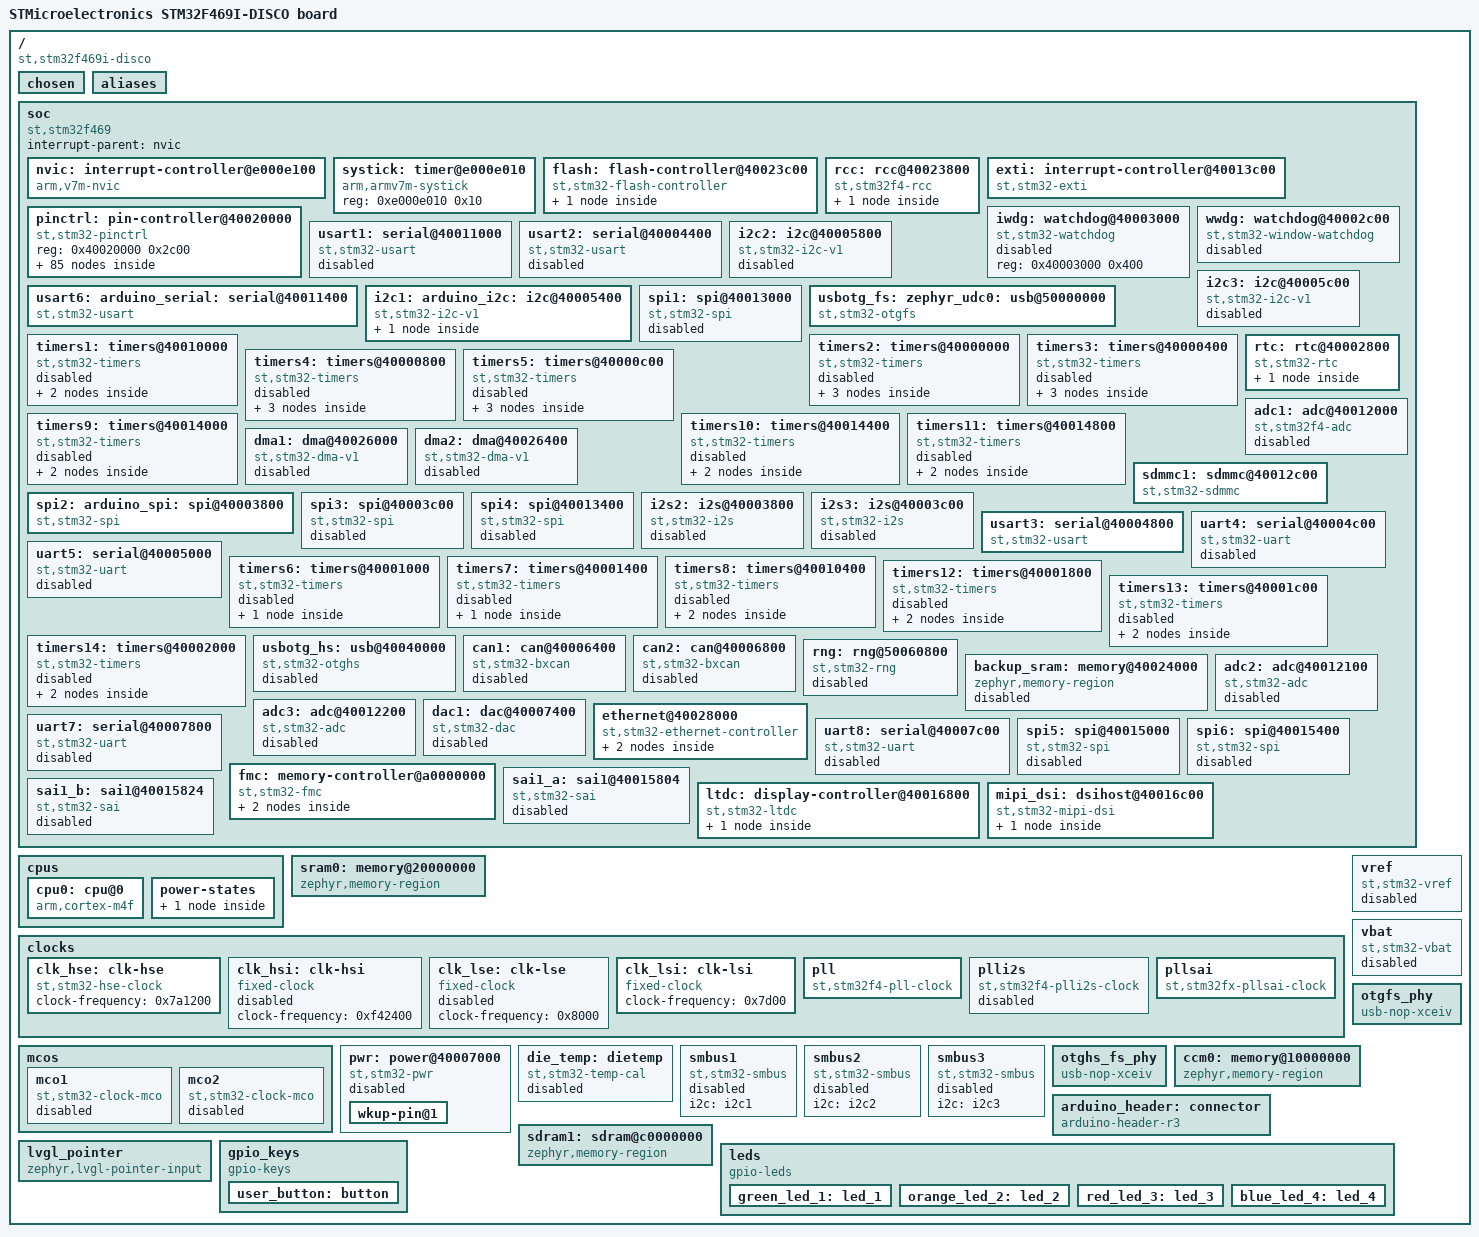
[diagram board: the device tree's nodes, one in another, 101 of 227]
/dts-v1/;

/* node '/' defined in zephyr/dts/common/skeleton.dtsi:9 */
/ {
	#address-cells = < 0x1 >;                            /* in zephyr/dts/common/skeleton.dtsi:10 */
	#size-cells = < 0x1 >;                               /* in zephyr/dts/common/skeleton.dtsi:11 */
	model = "STMicroelectronics STM32F469I-DISCO board"; /* in zephyr/boards/st/stm32f469i_disco/stm32f469i_disco.dts:14 */
	compatible = "st,stm32f469i-disco";                  /* in zephyr/boards/st/stm32f469i_disco/stm32f469i_disco.dts:15 */

	/* node '/chosen' defined in zephyr/dts/common/skeleton.dtsi:13 */
	chosen {
		zephyr,flash-controller = &flash;  /* in zephyr/dts/arm/st/f4/stm32f4.dtsi:27 */
		zephyr,cortex-m-idle-timer = &rtc; /* in zephyr/dts/arm/st/f4/stm32f4.dtsi:28 */
		zephyr,entropy = &rng;             /* in zephyr/dts/arm/st/f4/stm32f405.dtsi:13 */
		zephyr,console = &usart3;          /* in zephyr/boards/st/stm32f469i_disco/stm32f469i_disco.dts:18 */
		zephyr,shell-uart = &usart3;       /* in zephyr/boards/st/stm32f469i_disco/stm32f469i_disco.dts:19 */
		zephyr,sram = &sram0;              /* in zephyr/boards/st/stm32f469i_disco/stm32f469i_disco.dts:20 */
		zephyr,flash = &flash0;            /* in zephyr/boards/st/stm32f469i_disco/stm32f469i_disco.dts:21 */
		zephyr,ccm = &ccm0;                /* in zephyr/boards/st/stm32f469i_disco/stm32f469i_disco.dts:22 */
		zephyr,display = &ltdc;            /* in zephyr/boards/st/stm32f469i_disco/stm32f469i_disco.dts:23 */
		zephyr,touch = &ft5336;            /* in zephyr/boards/st/stm32f469i_disco/stm32f469i_disco.dts:24 */
	};

	/* node '/aliases' defined in zephyr/dts/common/skeleton.dtsi:15 */
	aliases {
		led0 = &green_led_1;  /* in zephyr/boards/st/stm32f469i_disco/stm32f469i_disco.dts:75 */
		led1 = &orange_led_2; /* in zephyr/boards/st/stm32f469i_disco/stm32f469i_disco.dts:76 */
		led2 = &red_led_3;    /* in zephyr/boards/st/stm32f469i_disco/stm32f469i_disco.dts:77 */
		led3 = &blue_led_4;   /* in zephyr/boards/st/stm32f469i_disco/stm32f469i_disco.dts:78 */
		sw0 = &user_button;   /* in zephyr/boards/st/stm32f469i_disco/stm32f469i_disco.dts:79 */
	};

	/* node '/soc' defined in zephyr/dts/arm/armv7-m.dtsi:6 */
	soc {
		#address-cells = < 0x1 >;     /* in zephyr/dts/arm/armv7-m.dtsi:7 */
		#size-cells = < 0x1 >;        /* in zephyr/dts/arm/armv7-m.dtsi:8 */
		interrupt-parent = < &nvic >; /* in zephyr/dts/arm/armv7-m.dtsi:10 */
		ranges;                       /* in zephyr/dts/arm/armv7-m.dtsi:11 */
		compatible = "st,stm32f469",
		             "st,stm32f4",
		             "simple-bus";    /* in zephyr/dts/arm/st/f4/stm32f469.dtsi:12 */

		/* node '/soc/interrupt-controller@e000e100' defined in zephyr/dts/arm/armv7-m.dtsi:13 */
		nvic: interrupt-controller@e000e100 {
			#address-cells = < 0x1 >;            /* in zephyr/dts/arm/armv7-m.dtsi:14 */
			compatible = "arm,v7m-nvic";         /* in zephyr/dts/arm/armv7-m.dtsi:15 */
			reg = < 0xe000e100 0xc00 >;          /* in zephyr/dts/arm/armv7-m.dtsi:16 */
			interrupt-controller;                /* in zephyr/dts/arm/armv7-m.dtsi:17 */
			#interrupt-cells = < 0x2 >;          /* in zephyr/dts/arm/armv7-m.dtsi:18 */
			arm,num-irq-priority-bits = < 0x4 >; /* in zephyr/dts/arm/st/f4/stm32f4.dtsi:676 */
			phandle = < 0x1 >;                   /* in zephyr/dts/arm/armv7-m.dtsi:10 */
		};

		/* node '/soc/timer@e000e010' defined in zephyr/dts/arm/armv7-m.dtsi:21 */
		systick: timer@e000e010 {
			compatible = "arm,armv7m-systick"; /* in zephyr/dts/arm/armv7-m.dtsi:22 */
			reg = < 0xe000e010 0x10 >;         /* in zephyr/dts/arm/armv7-m.dtsi:23 */
		};

		/* node '/soc/flash-controller@40023c00' defined in zephyr/dts/arm/st/f4/stm32f4.dtsi:111 */
		flash: flash-controller@40023c00 {
			compatible = "st,stm32-flash-controller",
			             "st,stm32f4-flash-controller"; /* in zephyr/dts/arm/st/f4/stm32f4.dtsi:112 */
			reg = < 0x40023c00 0x400 >;                 /* in zephyr/dts/arm/st/f4/stm32f4.dtsi:113 */
			interrupts = < 0x4 0x0 >;                   /* in zephyr/dts/arm/st/f4/stm32f4.dtsi:114 */
			#address-cells = < 0x1 >;                   /* in zephyr/dts/arm/st/f4/stm32f4.dtsi:116 */
			#size-cells = < 0x1 >;                      /* in zephyr/dts/arm/st/f4/stm32f4.dtsi:117 */

			/* node '/soc/flash-controller@40023c00/flash@8000000' defined in zephyr/dts/arm/st/f4/stm32f4.dtsi:119 */
			flash0: flash@8000000 {
				compatible = "st,stm32f4-nv-flash",
				             "st,stm32-nv-flash",
				             "soc-nv-flash";        /* in zephyr/dts/arm/st/f4/stm32f4.dtsi:120 */
				write-block-size = < 0x1 >;         /* in zephyr/dts/arm/st/f4/stm32f4.dtsi:123 */
				max-erase-time = < 0xfa0 >;         /* in zephyr/dts/arm/st/f4/stm32f4.dtsi:125 */
				reg = < 0x8000000 0x200000 >;       /* in zephyr/dts/arm/st/f4/stm32f469Xi.dtsi:23 */
			};
		};

		/* node '/soc/rcc@40023800' defined in zephyr/dts/arm/st/f4/stm32f4.dtsi:129 */
		rcc: rcc@40023800 {
			#clock-cells = < 0x2 >;          /* in zephyr/dts/arm/st/f4/stm32f4.dtsi:131 */
			reg = < 0x40023800 0x400 >;      /* in zephyr/dts/arm/st/f4/stm32f4.dtsi:132 */
			compatible = "st,stm32f4-rcc";   /* in zephyr/dts/arm/st/f4/stm32f427.dtsi:25 */
			clocks = < &pll >;               /* in zephyr/boards/st/stm32f469i_disco/stm32f469i_disco.dts:113 */
			clock-frequency = < 0xa037a00 >; /* in zephyr/boards/st/stm32f469i_disco/stm32f469i_disco.dts:114 */
			ahb-prescaler = < 0x1 >;         /* in zephyr/boards/st/stm32f469i_disco/stm32f469i_disco.dts:115 */
			apb1-prescaler = < 0x4 >;        /* in zephyr/boards/st/stm32f469i_disco/stm32f469i_disco.dts:116 */
			apb2-prescaler = < 0x2 >;        /* in zephyr/boards/st/stm32f469i_disco/stm32f469i_disco.dts:117 */
			phandle = < 0x3 >;               /* in zephyr/dts/arm/st/f4/stm32f4.dtsi:146 */

			/* node '/soc/rcc@40023800/reset-controller' defined in zephyr/dts/arm/st/f4/stm32f4.dtsi:134 */
			rctl: reset-controller {
				compatible = "st,stm32-rcc-rctl"; /* in zephyr/dts/arm/st/f4/stm32f4.dtsi:135 */
				#reset-cells = < 0x1 >;           /* in zephyr/dts/arm/st/f4/stm32f4.dtsi:136 */
				phandle = < 0x4 >;                /* in zephyr/dts/arm/st/f4/stm32f4.dtsi:245 */
			};
		};

		/* node '/soc/interrupt-controller@40013c00' defined in zephyr/dts/arm/st/f4/stm32f4.dtsi:140 */
		exti: interrupt-controller@40013c00 {
			compatible = "st,stm32-exti";  /* in zephyr/dts/arm/st/f4/stm32f4.dtsi:141 */
			interrupt-controller;          /* in zephyr/dts/arm/st/f4/stm32f4.dtsi:142 */
			#interrupt-cells = < 0x1 >;    /* in zephyr/dts/arm/st/f4/stm32f4.dtsi:143 */
			#address-cells = < 0x0 >;      /* in zephyr/dts/arm/st/f4/stm32f4.dtsi:144 */
			reg = < 0x40013c00 0x400 >;    /* in zephyr/dts/arm/st/f4/stm32f4.dtsi:145 */
			clocks = < &rcc 0x44 0x4000 >; /* in zephyr/dts/arm/st/f4/stm32f4.dtsi:146 */
			num-lines = < 0x20 >;          /* in zephyr/dts/arm/st/f4/stm32f4.dtsi:147 */
			interrupts = < 0x6 0x0 >,
			             < 0x7 0x0 >,
			             < 0x8 0x0 >,
			             < 0x9 0x0 >,
			             < 0xa 0x0 >,
			             < 0x17 0x0 >,
			             < 0x28 0x0 >;     /* in zephyr/dts/arm/st/f4/stm32f4.dtsi:148 */
			interrupt-names = "line0",
			                  "line1",
			                  "line2",
			                  "line3",
			                  "line4",
			                  "line5-9",
			                  "line10-15"; /* in zephyr/dts/arm/st/f4/stm32f4.dtsi:150 */
			line-ranges = < 0x0 0x1 >,
			              < 0x1 0x1 >,
			              < 0x2 0x1 >,
			              < 0x3 0x1 >,
			              < 0x4 0x1 >,
			              < 0x5 0x5 >,
			              < 0xa 0x6 >;     /* in zephyr/dts/arm/st/f4/stm32f4.dtsi:152 */
		};

		/* node '/soc/pin-controller@40020000' defined in zephyr/dts/arm/st/f4/stm32f4.dtsi:156 */
		pinctrl: pin-controller@40020000 {
			compatible = "st,stm32-pinctrl"; /* in zephyr/dts/arm/st/f4/stm32f4.dtsi:157 */
			#address-cells = < 0x1 >;        /* in zephyr/dts/arm/st/f4/stm32f4.dtsi:158 */
			#size-cells = < 0x1 >;           /* in zephyr/dts/arm/st/f4/stm32f4.dtsi:159 */
			reg = < 0x40020000 0x2c00 >;     /* in zephyr/dts/arm/st/f4/stm32f427.dtsi:29 */

			/* node '/soc/pin-controller@40020000/gpio@40020000' defined in zephyr/dts/arm/st/f4/stm32f4.dtsi:162 */
			gpioa: gpio@40020000 {
				compatible = "st,stm32-gpio"; /* in zephyr/dts/arm/st/f4/stm32f4.dtsi:163 */
				gpio-controller;              /* in zephyr/dts/arm/st/f4/stm32f4.dtsi:164 */
				#gpio-cells = < 0x2 >;        /* in zephyr/dts/arm/st/f4/stm32f4.dtsi:165 */
				reg = < 0x40020000 0x400 >;   /* in zephyr/dts/arm/st/f4/stm32f4.dtsi:166 */
				clocks = < &rcc 0x30 0x1 >;   /* in zephyr/dts/arm/st/f4/stm32f4.dtsi:167 */
				phandle = < 0x57 >;           /* in zephyr/boards/st/stm32f469i_disco/stm32f469i_disco.dts:249 */
			};

			/* node '/soc/pin-controller@40020000/gpio@40020400' defined in zephyr/dts/arm/st/f4/stm32f4.dtsi:170 */
			gpiob: gpio@40020400 {
				compatible = "st,stm32-gpio"; /* in zephyr/dts/arm/st/f4/stm32f4.dtsi:171 */
				gpio-controller;              /* in zephyr/dts/arm/st/f4/stm32f4.dtsi:172 */
				#gpio-cells = < 0x2 >;        /* in zephyr/dts/arm/st/f4/stm32f4.dtsi:173 */
				reg = < 0x40020400 0x400 >;   /* in zephyr/dts/arm/st/f4/stm32f4.dtsi:174 */
				clocks = < &rcc 0x30 0x2 >;   /* in zephyr/dts/arm/st/f4/stm32f4.dtsi:175 */
				phandle = < 0x5e >;           /* in zephyr/boards/st/stm32f469i_disco/arduino_r3_connector.dtsi:15 */
			};

			/* node '/soc/pin-controller@40020000/gpio@40020800' defined in zephyr/dts/arm/st/f4/stm32f4.dtsi:178 */
			gpioc: gpio@40020800 {
				compatible = "st,stm32-gpio"; /* in zephyr/dts/arm/st/f4/stm32f4.dtsi:179 */
				gpio-controller;              /* in zephyr/dts/arm/st/f4/stm32f4.dtsi:180 */
				#gpio-cells = < 0x2 >;        /* in zephyr/dts/arm/st/f4/stm32f4.dtsi:181 */
				reg = < 0x40020800 0x400 >;   /* in zephyr/dts/arm/st/f4/stm32f4.dtsi:182 */
				clocks = < &rcc 0x30 0x4 >;   /* in zephyr/dts/arm/st/f4/stm32f4.dtsi:183 */
				phandle = < 0x5f >;           /* in zephyr/boards/st/stm32f469i_disco/arduino_r3_connector.dtsi:15 */
			};

			/* node '/soc/pin-controller@40020000/gpio@40020c00' defined in zephyr/dts/arm/st/f4/stm32f4.dtsi:186 */
			gpiod: gpio@40020c00 {
				compatible = "st,stm32-gpio"; /* in zephyr/dts/arm/st/f4/stm32f4.dtsi:187 */
				gpio-controller;              /* in zephyr/dts/arm/st/f4/stm32f4.dtsi:188 */
				#gpio-cells = < 0x2 >;        /* in zephyr/dts/arm/st/f4/stm32f4.dtsi:189 */
				reg = < 0x40020c00 0x400 >;   /* in zephyr/dts/arm/st/f4/stm32f4.dtsi:190 */
				clocks = < &rcc 0x30 0x8 >;   /* in zephyr/dts/arm/st/f4/stm32f4.dtsi:191 */
				phandle = < 0x60 >;           /* in zephyr/boards/st/stm32f469i_disco/arduino_r3_connector.dtsi:15 */
			};

			/* node '/soc/pin-controller@40020000/gpio@40021000' defined in zephyr/dts/arm/st/f4/stm32f4.dtsi:194 */
			gpioe: gpio@40021000 {
				compatible = "st,stm32-gpio"; /* in zephyr/dts/arm/st/f4/stm32f4.dtsi:195 */
				gpio-controller;              /* in zephyr/dts/arm/st/f4/stm32f4.dtsi:196 */
				#gpio-cells = < 0x2 >;        /* in zephyr/dts/arm/st/f4/stm32f4.dtsi:197 */
				reg = < 0x40021000 0x400 >;   /* in zephyr/dts/arm/st/f4/stm32f4.dtsi:198 */
				clocks = < &rcc 0x30 0x10 >;  /* in zephyr/dts/arm/st/f4/stm32f4.dtsi:199 */
			};

			/* node '/soc/pin-controller@40020000/gpio@40021400' defined in zephyr/dts/arm/st/f4/stm32f4.dtsi:202 */
			gpiof: gpio@40021400 {
				compatible = "st,stm32-gpio"; /* in zephyr/dts/arm/st/f4/stm32f405.dtsi:27 */
				gpio-controller;              /* in zephyr/dts/arm/st/f4/stm32f405.dtsi:28 */
				#gpio-cells = < 0x2 >;        /* in zephyr/dts/arm/st/f4/stm32f405.dtsi:29 */
				reg = < 0x40021400 0x400 >;   /* in zephyr/dts/arm/st/f4/stm32f405.dtsi:30 */
				clocks = < &rcc 0x30 0x20 >;  /* in zephyr/dts/arm/st/f4/stm32f405.dtsi:31 */
			};

			/* node '/soc/pin-controller@40020000/gpio@40021800' defined in zephyr/dts/arm/st/f4/stm32f4.dtsi:210 */
			gpiog: gpio@40021800 {
				compatible = "st,stm32-gpio"; /* in zephyr/dts/arm/st/f4/stm32f405.dtsi:35 */
				gpio-controller;              /* in zephyr/dts/arm/st/f4/stm32f405.dtsi:36 */
				#gpio-cells = < 0x2 >;        /* in zephyr/dts/arm/st/f4/stm32f405.dtsi:37 */
				reg = < 0x40021800 0x400 >;   /* in zephyr/dts/arm/st/f4/stm32f405.dtsi:38 */
				clocks = < &rcc 0x30 0x40 >;  /* in zephyr/dts/arm/st/f4/stm32f405.dtsi:39 */
				phandle = < 0x13 >;           /* in zephyr/boards/st/stm32f469i_disco/stm32f469i_disco.dts:177 */
			};

			/* node '/soc/pin-controller@40020000/gpio@40021c00' defined in zephyr/dts/arm/st/f4/stm32f4.dtsi:218 */
			gpioh: gpio@40021c00 {
				compatible = "st,stm32-gpio"; /* in zephyr/dts/arm/st/f4/stm32f4.dtsi:219 */
				gpio-controller;              /* in zephyr/dts/arm/st/f4/stm32f4.dtsi:220 */
				#gpio-cells = < 0x2 >;        /* in zephyr/dts/arm/st/f4/stm32f4.dtsi:221 */
				reg = < 0x40021c00 0x400 >;   /* in zephyr/dts/arm/st/f4/stm32f4.dtsi:222 */
				clocks = < &rcc 0x30 0x80 >;  /* in zephyr/dts/arm/st/f4/stm32f4.dtsi:223 */
				phandle = < 0x17 >;           /* in zephyr/boards/st/stm32f469i_disco/stm32f469i_disco.dts:150 */
			};

			/* node '/soc/pin-controller@40020000/gpio@40022000' defined in zephyr/dts/arm/st/f4/stm32f405.dtsi:42 */
			gpioi: gpio@40022000 {
				compatible = "st,stm32-gpio"; /* in zephyr/dts/arm/st/f4/stm32f405.dtsi:43 */
				gpio-controller;              /* in zephyr/dts/arm/st/f4/stm32f405.dtsi:44 */
				#gpio-cells = < 0x2 >;        /* in zephyr/dts/arm/st/f4/stm32f405.dtsi:45 */
				reg = < 0x40022000 0x400 >;   /* in zephyr/dts/arm/st/f4/stm32f405.dtsi:46 */
				clocks = < &rcc 0x30 0x100 >; /* in zephyr/dts/arm/st/f4/stm32f405.dtsi:47 */
			};

			/* node '/soc/pin-controller@40020000/gpio@40022400' defined in zephyr/dts/arm/st/f4/stm32f427.dtsi:31 */
			gpioj: gpio@40022400 {
				compatible = "st,stm32-gpio"; /* in zephyr/dts/arm/st/f4/stm32f427.dtsi:32 */
				gpio-controller;              /* in zephyr/dts/arm/st/f4/stm32f427.dtsi:33 */
				#gpio-cells = < 0x2 >;        /* in zephyr/dts/arm/st/f4/stm32f427.dtsi:34 */
				reg = < 0x40022400 0x400 >;   /* in zephyr/dts/arm/st/f4/stm32f427.dtsi:35 */
				clocks = < &rcc 0x30 0x200 >; /* in zephyr/dts/arm/st/f4/stm32f427.dtsi:36 */
				phandle = < 0x9 >;            /* in zephyr/boards/st/stm32f469i_disco/stm32f469i_disco.dts:142 */
			};

			/* node '/soc/pin-controller@40020000/gpio@40022800' defined in zephyr/dts/arm/st/f4/stm32f427.dtsi:39 */
			gpiok: gpio@40022800 {
				compatible = "st,stm32-gpio"; /* in zephyr/dts/arm/st/f4/stm32f427.dtsi:40 */
				gpio-controller;              /* in zephyr/dts/arm/st/f4/stm32f427.dtsi:41 */
				#gpio-cells = < 0x2 >;        /* in zephyr/dts/arm/st/f4/stm32f427.dtsi:42 */
				reg = < 0x40022800 0x400 >;   /* in zephyr/dts/arm/st/f4/stm32f427.dtsi:43 */
				clocks = < &rcc 0x30 0x400 >; /* in zephyr/dts/arm/st/f4/stm32f427.dtsi:44 */
				phandle = < 0x61 >;           /* in zephyr/boards/st/stm32f469i_disco/stm32f469i_disco.dts:53 */
			};

			/* node '/soc/pin-controller@40020000/fmc_sdnwe_pc0' defined in modules/hal/stm32/dts/st/f4/stm32f469nihx-pinctrl.dtsi:1338 */
			fmc_sdnwe_pc0: fmc_sdnwe_pc0 {
				pinmux = < 0x40c >;            /* in modules/hal/stm32/dts/st/f4/stm32f469nihx-pinctrl.dtsi:1339 */
				bias-pull-up;                  /* in modules/hal/stm32/dts/st/f4/stm32f469nihx-pinctrl.dtsi:1340 */
				slew-rate = "very-high-speed"; /* in modules/hal/stm32/dts/st/f4/stm32f469nihx-pinctrl.dtsi:1341 */
				phandle = < 0x21 >;            /* in zephyr/boards/st/stm32f469i_disco/stm32f469i_disco.dts:182 */
			};

			/* node '/soc/pin-controller@40020000/fmc_d2_pd0' defined in modules/hal/stm32/dts/st/f4/stm32f469nihx-pinctrl.dtsi:1368 */
			fmc_d2_pd0: fmc_d2_pd0 {
				pinmux = < 0x60c >;            /* in modules/hal/stm32/dts/st/f4/stm32f469nihx-pinctrl.dtsi:1369 */
				bias-pull-up;                  /* in modules/hal/stm32/dts/st/f4/stm32f469nihx-pinctrl.dtsi:1370 */
				slew-rate = "very-high-speed"; /* in modules/hal/stm32/dts/st/f4/stm32f469nihx-pinctrl.dtsi:1371 */
				phandle = < 0x37 >;            /* in zephyr/boards/st/stm32f469i_disco/stm32f469i_disco.dts:182 */
			};

			/* node '/soc/pin-controller@40020000/fmc_d3_pd1' defined in modules/hal/stm32/dts/st/f4/stm32f469nihx-pinctrl.dtsi:1374 */
			fmc_d3_pd1: fmc_d3_pd1 {
				pinmux = < 0x62c >;            /* in modules/hal/stm32/dts/st/f4/stm32f469nihx-pinctrl.dtsi:1375 */
				bias-pull-up;                  /* in modules/hal/stm32/dts/st/f4/stm32f469nihx-pinctrl.dtsi:1376 */
				slew-rate = "very-high-speed"; /* in modules/hal/stm32/dts/st/f4/stm32f469nihx-pinctrl.dtsi:1377 */
				phandle = < 0x38 >;            /* in zephyr/boards/st/stm32f469i_disco/stm32f469i_disco.dts:182 */
			};

			/* node '/soc/pin-controller@40020000/fmc_d13_pd8' defined in modules/hal/stm32/dts/st/f4/stm32f469nihx-pinctrl.dtsi:1410 */
			fmc_d13_pd8: fmc_d13_pd8 {
				pinmux = < 0x70c >;            /* in modules/hal/stm32/dts/st/f4/stm32f469nihx-pinctrl.dtsi:1411 */
				bias-pull-up;                  /* in modules/hal/stm32/dts/st/f4/stm32f469nihx-pinctrl.dtsi:1412 */
				slew-rate = "very-high-speed"; /* in modules/hal/stm32/dts/st/f4/stm32f469nihx-pinctrl.dtsi:1413 */
				phandle = < 0x42 >;            /* in zephyr/boards/st/stm32f469i_disco/stm32f469i_disco.dts:182 */
			};

			/* node '/soc/pin-controller@40020000/fmc_d14_pd9' defined in modules/hal/stm32/dts/st/f4/stm32f469nihx-pinctrl.dtsi:1416 */
			fmc_d14_pd9: fmc_d14_pd9 {
				pinmux = < 0x72c >;            /* in modules/hal/stm32/dts/st/f4/stm32f469nihx-pinctrl.dtsi:1417 */
				bias-pull-up;                  /* in modules/hal/stm32/dts/st/f4/stm32f469nihx-pinctrl.dtsi:1418 */
				slew-rate = "very-high-speed"; /* in modules/hal/stm32/dts/st/f4/stm32f469nihx-pinctrl.dtsi:1419 */
				phandle = < 0x43 >;            /* in zephyr/boards/st/stm32f469i_disco/stm32f469i_disco.dts:182 */
			};

			/* node '/soc/pin-controller@40020000/fmc_d15_pd10' defined in modules/hal/stm32/dts/st/f4/stm32f469nihx-pinctrl.dtsi:1422 */
			fmc_d15_pd10: fmc_d15_pd10 {
				pinmux = < 0x74c >;            /* in modules/hal/stm32/dts/st/f4/stm32f469nihx-pinctrl.dtsi:1423 */
				bias-pull-up;                  /* in modules/hal/stm32/dts/st/f4/stm32f469nihx-pinctrl.dtsi:1424 */
				slew-rate = "very-high-speed"; /* in modules/hal/stm32/dts/st/f4/stm32f469nihx-pinctrl.dtsi:1425 */
				phandle = < 0x44 >;            /* in zephyr/boards/st/stm32f469i_disco/stm32f469i_disco.dts:182 */
			};

			/* node '/soc/pin-controller@40020000/fmc_d0_pd14' defined in modules/hal/stm32/dts/st/f4/stm32f469nihx-pinctrl.dtsi:1458 */
			fmc_d0_pd14: fmc_d0_pd14 {
				pinmux = < 0x7cc >;            /* in modules/hal/stm32/dts/st/f4/stm32f469nihx-pinctrl.dtsi:1459 */
				bias-pull-up;                  /* in modules/hal/stm32/dts/st/f4/stm32f469nihx-pinctrl.dtsi:1460 */
				slew-rate = "very-high-speed"; /* in modules/hal/stm32/dts/st/f4/stm32f469nihx-pinctrl.dtsi:1461 */
				phandle = < 0x35 >;            /* in zephyr/boards/st/stm32f469i_disco/stm32f469i_disco.dts:182 */
			};

			/* node '/soc/pin-controller@40020000/fmc_d1_pd15' defined in modules/hal/stm32/dts/st/f4/stm32f469nihx-pinctrl.dtsi:1464 */
			fmc_d1_pd15: fmc_d1_pd15 {
				pinmux = < 0x7ec >;            /* in modules/hal/stm32/dts/st/f4/stm32f469nihx-pinctrl.dtsi:1465 */
				bias-pull-up;                  /* in modules/hal/stm32/dts/st/f4/stm32f469nihx-pinctrl.dtsi:1466 */
				slew-rate = "very-high-speed"; /* in modules/hal/stm32/dts/st/f4/stm32f469nihx-pinctrl.dtsi:1467 */
				phandle = < 0x36 >;            /* in zephyr/boards/st/stm32f469i_disco/stm32f469i_disco.dts:182 */
			};

			/* node '/soc/pin-controller@40020000/fmc_nbl0_pe0' defined in modules/hal/stm32/dts/st/f4/stm32f469nihx-pinctrl.dtsi:1470 */
			fmc_nbl0_pe0: fmc_nbl0_pe0 {
				pinmux = < 0x80c >;            /* in modules/hal/stm32/dts/st/f4/stm32f469nihx-pinctrl.dtsi:1471 */
				bias-pull-up;                  /* in modules/hal/stm32/dts/st/f4/stm32f469nihx-pinctrl.dtsi:1472 */
				slew-rate = "very-high-speed"; /* in modules/hal/stm32/dts/st/f4/stm32f469nihx-pinctrl.dtsi:1473 */
				phandle = < 0x1c >;            /* in zephyr/boards/st/stm32f469i_disco/stm32f469i_disco.dts:182 */
			};

			/* node '/soc/pin-controller@40020000/fmc_nbl1_pe1' defined in modules/hal/stm32/dts/st/f4/stm32f469nihx-pinctrl.dtsi:1476 */
			fmc_nbl1_pe1: fmc_nbl1_pe1 {
				pinmux = < 0x82c >;            /* in modules/hal/stm32/dts/st/f4/stm32f469nihx-pinctrl.dtsi:1477 */
				bias-pull-up;                  /* in modules/hal/stm32/dts/st/f4/stm32f469nihx-pinctrl.dtsi:1478 */
				slew-rate = "very-high-speed"; /* in modules/hal/stm32/dts/st/f4/stm32f469nihx-pinctrl.dtsi:1479 */
				phandle = < 0x1d >;            /* in zephyr/boards/st/stm32f469i_disco/stm32f469i_disco.dts:182 */
			};

			/* node '/soc/pin-controller@40020000/fmc_d4_pe7' defined in modules/hal/stm32/dts/st/f4/stm32f469nihx-pinctrl.dtsi:1512 */
			fmc_d4_pe7: fmc_d4_pe7 {
				pinmux = < 0x8ec >;            /* in modules/hal/stm32/dts/st/f4/stm32f469nihx-pinctrl.dtsi:1513 */
				bias-pull-up;                  /* in modules/hal/stm32/dts/st/f4/stm32f469nihx-pinctrl.dtsi:1514 */
				slew-rate = "very-high-speed"; /* in modules/hal/stm32/dts/st/f4/stm32f469nihx-pinctrl.dtsi:1515 */
				phandle = < 0x39 >;            /* in zephyr/boards/st/stm32f469i_disco/stm32f469i_disco.dts:182 */
			};

			/* node '/soc/pin-controller@40020000/fmc_d5_pe8' defined in modules/hal/stm32/dts/st/f4/stm32f469nihx-pinctrl.dtsi:1518 */
			fmc_d5_pe8: fmc_d5_pe8 {
				pinmux = < 0x90c >;            /* in modules/hal/stm32/dts/st/f4/stm32f469nihx-pinctrl.dtsi:1519 */
				bias-pull-up;                  /* in modules/hal/stm32/dts/st/f4/stm32f469nihx-pinctrl.dtsi:1520 */
				slew-rate = "very-high-speed"; /* in modules/hal/stm32/dts/st/f4/stm32f469nihx-pinctrl.dtsi:1521 */
				phandle = < 0x3a >;            /* in zephyr/boards/st/stm32f469i_disco/stm32f469i_disco.dts:182 */
			};

			/* node '/soc/pin-controller@40020000/fmc_d6_pe9' defined in modules/hal/stm32/dts/st/f4/stm32f469nihx-pinctrl.dtsi:1524 */
			fmc_d6_pe9: fmc_d6_pe9 {
				pinmux = < 0x92c >;            /* in modules/hal/stm32/dts/st/f4/stm32f469nihx-pinctrl.dtsi:1525 */
				bias-pull-up;                  /* in modules/hal/stm32/dts/st/f4/stm32f469nihx-pinctrl.dtsi:1526 */
				slew-rate = "very-high-speed"; /* in modules/hal/stm32/dts/st/f4/stm32f469nihx-pinctrl.dtsi:1527 */
				phandle = < 0x3b >;            /* in zephyr/boards/st/stm32f469i_disco/stm32f469i_disco.dts:182 */
			};

			/* node '/soc/pin-controller@40020000/fmc_d7_pe10' defined in modules/hal/stm32/dts/st/f4/stm32f469nihx-pinctrl.dtsi:1530 */
			fmc_d7_pe10: fmc_d7_pe10 {
				pinmux = < 0x94c >;            /* in modules/hal/stm32/dts/st/f4/stm32f469nihx-pinctrl.dtsi:1531 */
				bias-pull-up;                  /* in modules/hal/stm32/dts/st/f4/stm32f469nihx-pinctrl.dtsi:1532 */
				slew-rate = "very-high-speed"; /* in modules/hal/stm32/dts/st/f4/stm32f469nihx-pinctrl.dtsi:1533 */
				phandle = < 0x3c >;            /* in zephyr/boards/st/stm32f469i_disco/stm32f469i_disco.dts:182 */
			};

			/* node '/soc/pin-controller@40020000/fmc_d8_pe11' defined in modules/hal/stm32/dts/st/f4/stm32f469nihx-pinctrl.dtsi:1536 */
			fmc_d8_pe11: fmc_d8_pe11 {
				pinmux = < 0x96c >;            /* in modules/hal/stm32/dts/st/f4/stm32f469nihx-pinctrl.dtsi:1537 */
				bias-pull-up;                  /* in modules/hal/stm32/dts/st/f4/stm32f469nihx-pinctrl.dtsi:1538 */
				slew-rate = "very-high-speed"; /* in modules/hal/stm32/dts/st/f4/stm32f469nihx-pinctrl.dtsi:1539 */
				phandle = < 0x3d >;            /* in zephyr/boards/st/stm32f469i_disco/stm32f469i_disco.dts:182 */
			};

			/* node '/soc/pin-controller@40020000/fmc_d9_pe12' defined in modules/hal/stm32/dts/st/f4/stm32f469nihx-pinctrl.dtsi:1542 */
			fmc_d9_pe12: fmc_d9_pe12 {
				pinmux = < 0x98c >;            /* in modules/hal/stm32/dts/st/f4/stm32f469nihx-pinctrl.dtsi:1543 */
				bias-pull-up;                  /* in modules/hal/stm32/dts/st/f4/stm32f469nihx-pinctrl.dtsi:1544 */
				slew-rate = "very-high-speed"; /* in modules/hal/stm32/dts/st/f4/stm32f469nihx-pinctrl.dtsi:1545 */
				phandle = < 0x3e >;            /* in zephyr/boards/st/stm32f469i_disco/stm32f469i_disco.dts:182 */
			};

			/* node '/soc/pin-controller@40020000/fmc_d10_pe13' defined in modules/hal/stm32/dts/st/f4/stm32f469nihx-pinctrl.dtsi:1548 */
			fmc_d10_pe13: fmc_d10_pe13 {
				pinmux = < 0x9ac >;            /* in modules/hal/stm32/dts/st/f4/stm32f469nihx-pinctrl.dtsi:1549 */
				bias-pull-up;                  /* in modules/hal/stm32/dts/st/f4/stm32f469nihx-pinctrl.dtsi:1550 */
				slew-rate = "very-high-speed"; /* in modules/hal/stm32/dts/st/f4/stm32f469nihx-pinctrl.dtsi:1551 */
				phandle = < 0x3f >;            /* in zephyr/boards/st/stm32f469i_disco/stm32f469i_disco.dts:182 */
			};

			/* node '/soc/pin-controller@40020000/fmc_d11_pe14' defined in modules/hal/stm32/dts/st/f4/stm32f469nihx-pinctrl.dtsi:1554 */
			fmc_d11_pe14: fmc_d11_pe14 {
				pinmux = < 0x9cc >;            /* in modules/hal/stm32/dts/st/f4/stm32f469nihx-pinctrl.dtsi:1555 */
				bias-pull-up;                  /* in modules/hal/stm32/dts/st/f4/stm32f469nihx-pinctrl.dtsi:1556 */
				slew-rate = "very-high-speed"; /* in modules/hal/stm32/dts/st/f4/stm32f469nihx-pinctrl.dtsi:1557 */
				phandle = < 0x40 >;            /* in zephyr/boards/st/stm32f469i_disco/stm32f469i_disco.dts:182 */
			};

			/* node '/soc/pin-controller@40020000/fmc_d12_pe15' defined in modules/hal/stm32/dts/st/f4/stm32f469nihx-pinctrl.dtsi:1560 */
			fmc_d12_pe15: fmc_d12_pe15 {
				pinmux = < 0x9ec >;            /* in modules/hal/stm32/dts/st/f4/stm32f469nihx-pinctrl.dtsi:1561 */
				bias-pull-up;                  /* in modules/hal/stm32/dts/st/f4/stm32f469nihx-pinctrl.dtsi:1562 */
				slew-rate = "very-high-speed"; /* in modules/hal/stm32/dts/st/f4/stm32f469nihx-pinctrl.dtsi:1563 */
				phandle = < 0x41 >;            /* in zephyr/boards/st/stm32f469i_disco/stm32f469i_disco.dts:182 */
			};

			/* node '/soc/pin-controller@40020000/fmc_a0_pf0' defined in modules/hal/stm32/dts/st/f4/stm32f469nihx-pinctrl.dtsi:1566 */
			fmc_a0_pf0: fmc_a0_pf0 {
				pinmux = < 0xa0c >;            /* in modules/hal/stm32/dts/st/f4/stm32f469nihx-pinctrl.dtsi:1567 */
				bias-pull-up;                  /* in modules/hal/stm32/dts/st/f4/stm32f469nihx-pinctrl.dtsi:1568 */
				slew-rate = "very-high-speed"; /* in modules/hal/stm32/dts/st/f4/stm32f469nihx-pinctrl.dtsi:1569 */
				phandle = < 0x26 >;            /* in zephyr/boards/st/stm32f469i_disco/stm32f469i_disco.dts:182 */
			};

			/* node '/soc/pin-controller@40020000/fmc_a1_pf1' defined in modules/hal/stm32/dts/st/f4/stm32f469nihx-pinctrl.dtsi:1572 */
			fmc_a1_pf1: fmc_a1_pf1 {
				pinmux = < 0xa2c >;            /* in modules/hal/stm32/dts/st/f4/stm32f469nihx-pinctrl.dtsi:1573 */
				bias-pull-up;                  /* in modules/hal/stm32/dts/st/f4/stm32f469nihx-pinctrl.dtsi:1574 */
				slew-rate = "very-high-speed"; /* in modules/hal/stm32/dts/st/f4/stm32f469nihx-pinctrl.dtsi:1575 */
				phandle = < 0x27 >;            /* in zephyr/boards/st/stm32f469i_disco/stm32f469i_disco.dts:182 */
			};

			/* node '/soc/pin-controller@40020000/fmc_a2_pf2' defined in modules/hal/stm32/dts/st/f4/stm32f469nihx-pinctrl.dtsi:1578 */
			fmc_a2_pf2: fmc_a2_pf2 {
				pinmux = < 0xa4c >;            /* in modules/hal/stm32/dts/st/f4/stm32f469nihx-pinctrl.dtsi:1579 */
				bias-pull-up;                  /* in modules/hal/stm32/dts/st/f4/stm32f469nihx-pinctrl.dtsi:1580 */
				slew-rate = "very-high-speed"; /* in modules/hal/stm32/dts/st/f4/stm32f469nihx-pinctrl.dtsi:1581 */
				phandle = < 0x28 >;            /* in zephyr/boards/st/stm32f469i_disco/stm32f469i_disco.dts:182 */
			};

			/* node '/soc/pin-controller@40020000/fmc_a3_pf3' defined in modules/hal/stm32/dts/st/f4/stm32f469nihx-pinctrl.dtsi:1584 */
			fmc_a3_pf3: fmc_a3_pf3 {
				pinmux = < 0xa6c >;            /* in modules/hal/stm32/dts/st/f4/stm32f469nihx-pinctrl.dtsi:1585 */
				bias-pull-up;                  /* in modules/hal/stm32/dts/st/f4/stm32f469nihx-pinctrl.dtsi:1586 */
				slew-rate = "very-high-speed"; /* in modules/hal/stm32/dts/st/f4/stm32f469nihx-pinctrl.dtsi:1587 */
				phandle = < 0x29 >;            /* in zephyr/boards/st/stm32f469i_disco/stm32f469i_disco.dts:182 */
			};

			/* node '/soc/pin-controller@40020000/fmc_a4_pf4' defined in modules/hal/stm32/dts/st/f4/stm32f469nihx-pinctrl.dtsi:1590 */
			fmc_a4_pf4: fmc_a4_pf4 {
				pinmux = < 0xa8c >;            /* in modules/hal/stm32/dts/st/f4/stm32f469nihx-pinctrl.dtsi:1591 */
				bias-pull-up;                  /* in modules/hal/stm32/dts/st/f4/stm32f469nihx-pinctrl.dtsi:1592 */
				slew-rate = "very-high-speed"; /* in modules/hal/stm32/dts/st/f4/stm32f469nihx-pinctrl.dtsi:1593 */
				phandle = < 0x2a >;            /* in zephyr/boards/st/stm32f469i_disco/stm32f469i_disco.dts:182 */
			};

			/* node '/soc/pin-controller@40020000/fmc_a5_pf5' defined in modules/hal/stm32/dts/st/f4/stm32f469nihx-pinctrl.dtsi:1596 */
			fmc_a5_pf5: fmc_a5_pf5 {
				pinmux = < 0xaac >;            /* in modules/hal/stm32/dts/st/f4/stm32f469nihx-pinctrl.dtsi:1597 */
				bias-pull-up;                  /* in modules/hal/stm32/dts/st/f4/stm32f469nihx-pinctrl.dtsi:1598 */
				slew-rate = "very-high-speed"; /* in modules/hal/stm32/dts/st/f4/stm32f469nihx-pinctrl.dtsi:1599 */
				phandle = < 0x2b >;            /* in zephyr/boards/st/stm32f469i_disco/stm32f469i_disco.dts:182 */
			};

			/* node '/soc/pin-controller@40020000/fmc_sdnras_pf11' defined in modules/hal/stm32/dts/st/f4/stm32f469nihx-pinctrl.dtsi:1602 */
			fmc_sdnras_pf11: fmc_sdnras_pf11 {
				pinmux = < 0xb6c >;            /* in modules/hal/stm32/dts/st/f4/stm32f469nihx-pinctrl.dtsi:1603 */
				bias-pull-up;                  /* in modules/hal/stm32/dts/st/f4/stm32f469nihx-pinctrl.dtsi:1604 */
				slew-rate = "very-high-speed"; /* in modules/hal/stm32/dts/st/f4/stm32f469nihx-pinctrl.dtsi:1605 */
				phandle = < 0x24 >;            /* in zephyr/boards/st/stm32f469i_disco/stm32f469i_disco.dts:182 */
			};

			/* node '/soc/pin-controller@40020000/fmc_a6_pf12' defined in modules/hal/stm32/dts/st/f4/stm32f469nihx-pinctrl.dtsi:1608 */
			fmc_a6_pf12: fmc_a6_pf12 {
				pinmux = < 0xb8c >;            /* in modules/hal/stm32/dts/st/f4/stm32f469nihx-pinctrl.dtsi:1609 */
				bias-pull-up;                  /* in modules/hal/stm32/dts/st/f4/stm32f469nihx-pinctrl.dtsi:1610 */
				slew-rate = "very-high-speed"; /* in modules/hal/stm32/dts/st/f4/stm32f469nihx-pinctrl.dtsi:1611 */
				phandle = < 0x2c >;            /* in zephyr/boards/st/stm32f469i_disco/stm32f469i_disco.dts:182 */
			};

			/* node '/soc/pin-controller@40020000/fmc_a7_pf13' defined in modules/hal/stm32/dts/st/f4/stm32f469nihx-pinctrl.dtsi:1614 */
			fmc_a7_pf13: fmc_a7_pf13 {
				pinmux = < 0xbac >;            /* in modules/hal/stm32/dts/st/f4/stm32f469nihx-pinctrl.dtsi:1615 */
				bias-pull-up;                  /* in modules/hal/stm32/dts/st/f4/stm32f469nihx-pinctrl.dtsi:1616 */
				slew-rate = "very-high-speed"; /* in modules/hal/stm32/dts/st/f4/stm32f469nihx-pinctrl.dtsi:1617 */
				phandle = < 0x2d >;            /* in zephyr/boards/st/stm32f469i_disco/stm32f469i_disco.dts:182 */
			};

			/* node '/soc/pin-controller@40020000/fmc_a8_pf14' defined in modules/hal/stm32/dts/st/f4/stm32f469nihx-pinctrl.dtsi:1620 */
			fmc_a8_pf14: fmc_a8_pf14 {
				pinmux = < 0xbcc >;            /* in modules/hal/stm32/dts/st/f4/stm32f469nihx-pinctrl.dtsi:1621 */
				bias-pull-up;                  /* in modules/hal/stm32/dts/st/f4/stm32f469nihx-pinctrl.dtsi:1622 */
				slew-rate = "very-high-speed"; /* in modules/hal/stm32/dts/st/f4/stm32f469nihx-pinctrl.dtsi:1623 */
				phandle = < 0x2e >;            /* in zephyr/boards/st/stm32f469i_disco/stm32f469i_disco.dts:182 */
			};

			/* node '/soc/pin-controller@40020000/fmc_a9_pf15' defined in modules/hal/stm32/dts/st/f4/stm32f469nihx-pinctrl.dtsi:1626 */
			fmc_a9_pf15: fmc_a9_pf15 {
				pinmux = < 0xbec >;            /* in modules/hal/stm32/dts/st/f4/stm32f469nihx-pinctrl.dtsi:1627 */
				bias-pull-up;                  /* in modules/hal/stm32/dts/st/f4/stm32f469nihx-pinctrl.dtsi:1628 */
				slew-rate = "very-high-speed"; /* in modules/hal/stm32/dts/st/f4/stm32f469nihx-pinctrl.dtsi:1629 */
				phandle = < 0x2f >;            /* in zephyr/boards/st/stm32f469i_disco/stm32f469i_disco.dts:182 */
			};

			/* node '/soc/pin-controller@40020000/fmc_a10_pg0' defined in modules/hal/stm32/dts/st/f4/stm32f469nihx-pinctrl.dtsi:1632 */
			fmc_a10_pg0: fmc_a10_pg0 {
				pinmux = < 0xc0c >;            /* in modules/hal/stm32/dts/st/f4/stm32f469nihx-pinctrl.dtsi:1633 */
				bias-pull-up;                  /* in modules/hal/stm32/dts/st/f4/stm32f469nihx-pinctrl.dtsi:1634 */
				slew-rate = "very-high-speed"; /* in modules/hal/stm32/dts/st/f4/stm32f469nihx-pinctrl.dtsi:1635 */
				phandle = < 0x30 >;            /* in zephyr/boards/st/stm32f469i_disco/stm32f469i_disco.dts:182 */
			};

			/* node '/soc/pin-controller@40020000/fmc_a11_pg1' defined in modules/hal/stm32/dts/st/f4/stm32f469nihx-pinctrl.dtsi:1638 */
			fmc_a11_pg1: fmc_a11_pg1 {
				pinmux = < 0xc2c >;            /* in modules/hal/stm32/dts/st/f4/stm32f469nihx-pinctrl.dtsi:1639 */
				bias-pull-up;                  /* in modules/hal/stm32/dts/st/f4/stm32f469nihx-pinctrl.dtsi:1640 */
				slew-rate = "very-high-speed"; /* in modules/hal/stm32/dts/st/f4/stm32f469nihx-pinctrl.dtsi:1641 */
				phandle = < 0x31 >;            /* in zephyr/boards/st/stm32f469i_disco/stm32f469i_disco.dts:182 */
			};

			/* node '/soc/pin-controller@40020000/fmc_a12_pg2' defined in modules/hal/stm32/dts/st/f4/stm32f469nihx-pinctrl.dtsi:1644 */
			fmc_a12_pg2: fmc_a12_pg2 {
				pinmux = < 0xc4c >;            /* in modules/hal/stm32/dts/st/f4/stm32f469nihx-pinctrl.dtsi:1645 */
				bias-pull-up;                  /* in modules/hal/stm32/dts/st/f4/stm32f469nihx-pinctrl.dtsi:1646 */
				slew-rate = "very-high-speed"; /* in modules/hal/stm32/dts/st/f4/stm32f469nihx-pinctrl.dtsi:1647 */
				phandle = < 0x32 >;            /* in zephyr/boards/st/stm32f469i_disco/stm32f469i_disco.dts:182 */
			};

			/* node '/soc/pin-controller@40020000/fmc_a14_pg4' defined in modules/hal/stm32/dts/st/f4/stm32f469nihx-pinctrl.dtsi:1656 */
			fmc_a14_pg4: fmc_a14_pg4 {
				pinmux = < 0xc8c >;            /* in modules/hal/stm32/dts/st/f4/stm32f469nihx-pinctrl.dtsi:1657 */
				bias-pull-up;                  /* in modules/hal/stm32/dts/st/f4/stm32f469nihx-pinctrl.dtsi:1658 */
				slew-rate = "very-high-speed"; /* in modules/hal/stm32/dts/st/f4/stm32f469nihx-pinctrl.dtsi:1659 */
				phandle = < 0x33 >;            /* in zephyr/boards/st/stm32f469i_disco/stm32f469i_disco.dts:182 */
			};

			/* node '/soc/pin-controller@40020000/fmc_a15_pg5' defined in modules/hal/stm32/dts/st/f4/stm32f469nihx-pinctrl.dtsi:1662 */
			fmc_a15_pg5: fmc_a15_pg5 {
				pinmux = < 0xcac >;            /* in modules/hal/stm32/dts/st/f4/stm32f469nihx-pinctrl.dtsi:1663 */
				bias-pull-up;                  /* in modules/hal/stm32/dts/st/f4/stm32f469nihx-pinctrl.dtsi:1664 */
				slew-rate = "very-high-speed"; /* in modules/hal/stm32/dts/st/f4/stm32f469nihx-pinctrl.dtsi:1665 */
				phandle = < 0x34 >;            /* in zephyr/boards/st/stm32f469i_disco/stm32f469i_disco.dts:182 */
			};

			/* node '/soc/pin-controller@40020000/fmc_sdclk_pg8' defined in modules/hal/stm32/dts/st/f4/stm32f469nihx-pinctrl.dtsi:1674 */
			fmc_sdclk_pg8: fmc_sdclk_pg8 {
				pinmux = < 0xd0c >;            /* in modules/hal/stm32/dts/st/f4/stm32f469nihx-pinctrl.dtsi:1675 */
				bias-pull-up;                  /* in modules/hal/stm32/dts/st/f4/stm32f469nihx-pinctrl.dtsi:1676 */
				slew-rate = "very-high-speed"; /* in modules/hal/stm32/dts/st/f4/stm32f469nihx-pinctrl.dtsi:1677 */
				phandle = < 0x20 >;            /* in zephyr/boards/st/stm32f469i_disco/stm32f469i_disco.dts:182 */
			};

			/* node '/soc/pin-controller@40020000/fmc_sdncas_pg15' defined in modules/hal/stm32/dts/st/f4/stm32f469nihx-pinctrl.dtsi:1716 */
			fmc_sdncas_pg15: fmc_sdncas_pg15 {
				pinmux = < 0xdec >;            /* in modules/hal/stm32/dts/st/f4/stm32f469nihx-pinctrl.dtsi:1717 */
				bias-pull-up;                  /* in modules/hal/stm32/dts/st/f4/stm32f469nihx-pinctrl.dtsi:1718 */
				slew-rate = "very-high-speed"; /* in modules/hal/stm32/dts/st/f4/stm32f469nihx-pinctrl.dtsi:1719 */
				phandle = < 0x25 >;            /* in zephyr/boards/st/stm32f469i_disco/stm32f469i_disco.dts:182 */
			};

			/* node '/soc/pin-controller@40020000/fmc_sdcke0_ph2' defined in modules/hal/stm32/dts/st/f4/stm32f469nihx-pinctrl.dtsi:1722 */
			fmc_sdcke0_ph2: fmc_sdcke0_ph2 {
				pinmux = < 0xe4c >;            /* in modules/hal/stm32/dts/st/f4/stm32f469nihx-pinctrl.dtsi:1723 */
				bias-pull-up;                  /* in modules/hal/stm32/dts/st/f4/stm32f469nihx-pinctrl.dtsi:1724 */
				slew-rate = "very-high-speed"; /* in modules/hal/stm32/dts/st/f4/stm32f469nihx-pinctrl.dtsi:1725 */
				phandle = < 0x22 >;            /* in zephyr/boards/st/stm32f469i_disco/stm32f469i_disco.dts:182 */
			};

			/* node '/soc/pin-controller@40020000/fmc_sdne0_ph3' defined in modules/hal/stm32/dts/st/f4/stm32f469nihx-pinctrl.dtsi:1728 */
			fmc_sdne0_ph3: fmc_sdne0_ph3 {
				pinmux = < 0xe6c >;            /* in modules/hal/stm32/dts/st/f4/stm32f469nihx-pinctrl.dtsi:1729 */
				bias-pull-up;                  /* in modules/hal/stm32/dts/st/f4/stm32f469nihx-pinctrl.dtsi:1730 */
				slew-rate = "very-high-speed"; /* in modules/hal/stm32/dts/st/f4/stm32f469nihx-pinctrl.dtsi:1731 */
				phandle = < 0x23 >;            /* in zephyr/boards/st/stm32f469i_disco/stm32f469i_disco.dts:182 */
			};

			/* node '/soc/pin-controller@40020000/fmc_d16_ph8' defined in modules/hal/stm32/dts/st/f4/stm32f469nihx-pinctrl.dtsi:1752 */
			fmc_d16_ph8: fmc_d16_ph8 {
				pinmux = < 0xf0c >;            /* in modules/hal/stm32/dts/st/f4/stm32f469nihx-pinctrl.dtsi:1753 */
				bias-pull-up;                  /* in modules/hal/stm32/dts/st/f4/stm32f469nihx-pinctrl.dtsi:1754 */
				slew-rate = "very-high-speed"; /* in modules/hal/stm32/dts/st/f4/stm32f469nihx-pinctrl.dtsi:1755 */
				phandle = < 0x45 >;            /* in zephyr/boards/st/stm32f469i_disco/stm32f469i_disco.dts:182 */
			};

			/* node '/soc/pin-controller@40020000/fmc_d17_ph9' defined in modules/hal/stm32/dts/st/f4/stm32f469nihx-pinctrl.dtsi:1758 */
			fmc_d17_ph9: fmc_d17_ph9 {
				pinmux = < 0xf2c >;            /* in modules/hal/stm32/dts/st/f4/stm32f469nihx-pinctrl.dtsi:1759 */
				bias-pull-up;                  /* in modules/hal/stm32/dts/st/f4/stm32f469nihx-pinctrl.dtsi:1760 */
				slew-rate = "very-high-speed"; /* in modules/hal/stm32/dts/st/f4/stm32f469nihx-pinctrl.dtsi:1761 */
				phandle = < 0x46 >;            /* in zephyr/boards/st/stm32f469i_disco/stm32f469i_disco.dts:182 */
			};

			/* node '/soc/pin-controller@40020000/fmc_d18_ph10' defined in modules/hal/stm32/dts/st/f4/stm32f469nihx-pinctrl.dtsi:1764 */
			fmc_d18_ph10: fmc_d18_ph10 {
				pinmux = < 0xf4c >;            /* in modules/hal/stm32/dts/st/f4/stm32f469nihx-pinctrl.dtsi:1765 */
				bias-pull-up;                  /* in modules/hal/stm32/dts/st/f4/stm32f469nihx-pinctrl.dtsi:1766 */
				slew-rate = "very-high-speed"; /* in modules/hal/stm32/dts/st/f4/stm32f469nihx-pinctrl.dtsi:1767 */
				phandle = < 0x47 >;            /* in zephyr/boards/st/stm32f469i_disco/stm32f469i_disco.dts:182 */
			};

			/* node '/soc/pin-controller@40020000/fmc_d19_ph11' defined in modules/hal/stm32/dts/st/f4/stm32f469nihx-pinctrl.dtsi:1770 */
			fmc_d19_ph11: fmc_d19_ph11 {
				pinmux = < 0xf6c >;            /* in modules/hal/stm32/dts/st/f4/stm32f469nihx-pinctrl.dtsi:1771 */
				bias-pull-up;                  /* in modules/hal/stm32/dts/st/f4/stm32f469nihx-pinctrl.dtsi:1772 */
				slew-rate = "very-high-speed"; /* in modules/hal/stm32/dts/st/f4/stm32f469nihx-pinctrl.dtsi:1773 */
				phandle = < 0x48 >;            /* in zephyr/boards/st/stm32f469i_disco/stm32f469i_disco.dts:182 */
			};

			/* node '/soc/pin-controller@40020000/fmc_d20_ph12' defined in modules/hal/stm32/dts/st/f4/stm32f469nihx-pinctrl.dtsi:1776 */
			fmc_d20_ph12: fmc_d20_ph12 {
				pinmux = < 0xf8c >;            /* in modules/hal/stm32/dts/st/f4/stm32f469nihx-pinctrl.dtsi:1777 */
				bias-pull-up;                  /* in modules/hal/stm32/dts/st/f4/stm32f469nihx-pinctrl.dtsi:1778 */
				slew-rate = "very-high-speed"; /* in modules/hal/stm32/dts/st/f4/stm32f469nihx-pinctrl.dtsi:1779 */
				phandle = < 0x49 >;            /* in zephyr/boards/st/stm32f469i_disco/stm32f469i_disco.dts:182 */
			};

			/* node '/soc/pin-controller@40020000/fmc_d21_ph13' defined in modules/hal/stm32/dts/st/f4/stm32f469nihx-pinctrl.dtsi:1782 */
			fmc_d21_ph13: fmc_d21_ph13 {
				pinmux = < 0xfac >;            /* in modules/hal/stm32/dts/st/f4/stm32f469nihx-pinctrl.dtsi:1783 */
				bias-pull-up;                  /* in modules/hal/stm32/dts/st/f4/stm32f469nihx-pinctrl.dtsi:1784 */
				slew-rate = "very-high-speed"; /* in modules/hal/stm32/dts/st/f4/stm32f469nihx-pinctrl.dtsi:1785 */
				phandle = < 0x4a >;            /* in zephyr/boards/st/stm32f469i_disco/stm32f469i_disco.dts:182 */
			};

			/* node '/soc/pin-controller@40020000/fmc_d22_ph14' defined in modules/hal/stm32/dts/st/f4/stm32f469nihx-pinctrl.dtsi:1788 */
			fmc_d22_ph14: fmc_d22_ph14 {
				pinmux = < 0xfcc >;            /* in modules/hal/stm32/dts/st/f4/stm32f469nihx-pinctrl.dtsi:1789 */
				bias-pull-up;                  /* in modules/hal/stm32/dts/st/f4/stm32f469nihx-pinctrl.dtsi:1790 */
				slew-rate = "very-high-speed"; /* in modules/hal/stm32/dts/st/f4/stm32f469nihx-pinctrl.dtsi:1791 */
				phandle = < 0x4b >;            /* in zephyr/boards/st/stm32f469i_disco/stm32f469i_disco.dts:182 */
			};

			/* node '/soc/pin-controller@40020000/fmc_d23_ph15' defined in modules/hal/stm32/dts/st/f4/stm32f469nihx-pinctrl.dtsi:1794 */
			fmc_d23_ph15: fmc_d23_ph15 {
				pinmux = < 0xfec >;            /* in modules/hal/stm32/dts/st/f4/stm32f469nihx-pinctrl.dtsi:1795 */
				bias-pull-up;                  /* in modules/hal/stm32/dts/st/f4/stm32f469nihx-pinctrl.dtsi:1796 */
				slew-rate = "very-high-speed"; /* in modules/hal/stm32/dts/st/f4/stm32f469nihx-pinctrl.dtsi:1797 */
				phandle = < 0x4c >;            /* in zephyr/boards/st/stm32f469i_disco/stm32f469i_disco.dts:182 */
			};

			/* node '/soc/pin-controller@40020000/fmc_d24_pi0' defined in modules/hal/stm32/dts/st/f4/stm32f469nihx-pinctrl.dtsi:1800 */
			fmc_d24_pi0: fmc_d24_pi0 {
				pinmux = < 0x100c >;           /* in modules/hal/stm32/dts/st/f4/stm32f469nihx-pinctrl.dtsi:1801 */
				bias-pull-up;                  /* in modules/hal/stm32/dts/st/f4/stm32f469nihx-pinctrl.dtsi:1802 */
				slew-rate = "very-high-speed"; /* in modules/hal/stm32/dts/st/f4/stm32f469nihx-pinctrl.dtsi:1803 */
				phandle = < 0x4d >;            /* in zephyr/boards/st/stm32f469i_disco/stm32f469i_disco.dts:182 */
			};

			/* node '/soc/pin-controller@40020000/fmc_d25_pi1' defined in modules/hal/stm32/dts/st/f4/stm32f469nihx-pinctrl.dtsi:1806 */
			fmc_d25_pi1: fmc_d25_pi1 {
				pinmux = < 0x102c >;           /* in modules/hal/stm32/dts/st/f4/stm32f469nihx-pinctrl.dtsi:1807 */
				bias-pull-up;                  /* in modules/hal/stm32/dts/st/f4/stm32f469nihx-pinctrl.dtsi:1808 */
				slew-rate = "very-high-speed"; /* in modules/hal/stm32/dts/st/f4/stm32f469nihx-pinctrl.dtsi:1809 */
				phandle = < 0x4e >;            /* in zephyr/boards/st/stm32f469i_disco/stm32f469i_disco.dts:182 */
			};

			/* node '/soc/pin-controller@40020000/fmc_d26_pi2' defined in modules/hal/stm32/dts/st/f4/stm32f469nihx-pinctrl.dtsi:1812 */
			fmc_d26_pi2: fmc_d26_pi2 {
				pinmux = < 0x104c >;           /* in modules/hal/stm32/dts/st/f4/stm32f469nihx-pinctrl.dtsi:1813 */
				bias-pull-up;                  /* in modules/hal/stm32/dts/st/f4/stm32f469nihx-pinctrl.dtsi:1814 */
				slew-rate = "very-high-speed"; /* in modules/hal/stm32/dts/st/f4/stm32f469nihx-pinctrl.dtsi:1815 */
				phandle = < 0x4f >;            /* in zephyr/boards/st/stm32f469i_disco/stm32f469i_disco.dts:182 */
			};

			/* node '/soc/pin-controller@40020000/fmc_d27_pi3' defined in modules/hal/stm32/dts/st/f4/stm32f469nihx-pinctrl.dtsi:1818 */
			fmc_d27_pi3: fmc_d27_pi3 {
				pinmux = < 0x106c >;           /* in modules/hal/stm32/dts/st/f4/stm32f469nihx-pinctrl.dtsi:1819 */
				bias-pull-up;                  /* in modules/hal/stm32/dts/st/f4/stm32f469nihx-pinctrl.dtsi:1820 */
				slew-rate = "very-high-speed"; /* in modules/hal/stm32/dts/st/f4/stm32f469nihx-pinctrl.dtsi:1821 */
				phandle = < 0x50 >;            /* in zephyr/boards/st/stm32f469i_disco/stm32f469i_disco.dts:182 */
			};

			/* node '/soc/pin-controller@40020000/fmc_nbl2_pi4' defined in modules/hal/stm32/dts/st/f4/stm32f469nihx-pinctrl.dtsi:1824 */
			fmc_nbl2_pi4: fmc_nbl2_pi4 {
				pinmux = < 0x108c >;           /* in modules/hal/stm32/dts/st/f4/stm32f469nihx-pinctrl.dtsi:1825 */
				bias-pull-up;                  /* in modules/hal/stm32/dts/st/f4/stm32f469nihx-pinctrl.dtsi:1826 */
				slew-rate = "very-high-speed"; /* in modules/hal/stm32/dts/st/f4/stm32f469nihx-pinctrl.dtsi:1827 */
				phandle = < 0x1e >;            /* in zephyr/boards/st/stm32f469i_disco/stm32f469i_disco.dts:182 */
			};

			/* node '/soc/pin-controller@40020000/fmc_nbl3_pi5' defined in modules/hal/stm32/dts/st/f4/stm32f469nihx-pinctrl.dtsi:1830 */
			fmc_nbl3_pi5: fmc_nbl3_pi5 {
				pinmux = < 0x10ac >;           /* in modules/hal/stm32/dts/st/f4/stm32f469nihx-pinctrl.dtsi:1831 */
				bias-pull-up;                  /* in modules/hal/stm32/dts/st/f4/stm32f469nihx-pinctrl.dtsi:1832 */
				slew-rate = "very-high-speed"; /* in modules/hal/stm32/dts/st/f4/stm32f469nihx-pinctrl.dtsi:1833 */
				phandle = < 0x1f >;            /* in zephyr/boards/st/stm32f469i_disco/stm32f469i_disco.dts:182 */
			};

			/* node '/soc/pin-controller@40020000/fmc_d28_pi6' defined in modules/hal/stm32/dts/st/f4/stm32f469nihx-pinctrl.dtsi:1836 */
			fmc_d28_pi6: fmc_d28_pi6 {
				pinmux = < 0x10cc >;           /* in modules/hal/stm32/dts/st/f4/stm32f469nihx-pinctrl.dtsi:1837 */
				bias-pull-up;                  /* in modules/hal/stm32/dts/st/f4/stm32f469nihx-pinctrl.dtsi:1838 */
				slew-rate = "very-high-speed"; /* in modules/hal/stm32/dts/st/f4/stm32f469nihx-pinctrl.dtsi:1839 */
				phandle = < 0x51 >;            /* in zephyr/boards/st/stm32f469i_disco/stm32f469i_disco.dts:182 */
			};

			/* node '/soc/pin-controller@40020000/fmc_d29_pi7' defined in modules/hal/stm32/dts/st/f4/stm32f469nihx-pinctrl.dtsi:1842 */
			fmc_d29_pi7: fmc_d29_pi7 {
				pinmux = < 0x10ec >;           /* in modules/hal/stm32/dts/st/f4/stm32f469nihx-pinctrl.dtsi:1843 */
				bias-pull-up;                  /* in modules/hal/stm32/dts/st/f4/stm32f469nihx-pinctrl.dtsi:1844 */
				slew-rate = "very-high-speed"; /* in modules/hal/stm32/dts/st/f4/stm32f469nihx-pinctrl.dtsi:1845 */
				phandle = < 0x52 >;            /* in zephyr/boards/st/stm32f469i_disco/stm32f469i_disco.dts:182 */
			};

			/* node '/soc/pin-controller@40020000/fmc_d30_pi9' defined in modules/hal/stm32/dts/st/f4/stm32f469nihx-pinctrl.dtsi:1848 */
			fmc_d30_pi9: fmc_d30_pi9 {
				pinmux = < 0x112c >;           /* in modules/hal/stm32/dts/st/f4/stm32f469nihx-pinctrl.dtsi:1849 */
				bias-pull-up;                  /* in modules/hal/stm32/dts/st/f4/stm32f469nihx-pinctrl.dtsi:1850 */
				slew-rate = "very-high-speed"; /* in modules/hal/stm32/dts/st/f4/stm32f469nihx-pinctrl.dtsi:1851 */
				phandle = < 0x53 >;            /* in zephyr/boards/st/stm32f469i_disco/stm32f469i_disco.dts:182 */
			};

			/* node '/soc/pin-controller@40020000/fmc_d31_pi10' defined in modules/hal/stm32/dts/st/f4/stm32f469nihx-pinctrl.dtsi:1854 */
			fmc_d31_pi10: fmc_d31_pi10 {
				pinmux = < 0x114c >;           /* in modules/hal/stm32/dts/st/f4/stm32f469nihx-pinctrl.dtsi:1855 */
				bias-pull-up;                  /* in modules/hal/stm32/dts/st/f4/stm32f469nihx-pinctrl.dtsi:1856 */
				slew-rate = "very-high-speed"; /* in modules/hal/stm32/dts/st/f4/stm32f469nihx-pinctrl.dtsi:1857 */
				phandle = < 0x54 >;            /* in zephyr/boards/st/stm32f469i_disco/stm32f469i_disco.dts:182 */
			};

			/* node '/soc/pin-controller@40020000/i2c1_scl_pb8' defined in modules/hal/stm32/dts/st/f4/stm32f469nihx-pinctrl.dtsi:1868 */
			i2c1_scl_pb8: i2c1_scl_pb8 {
				pinmux = < 0x304 >; /* in modules/hal/stm32/dts/st/f4/stm32f469nihx-pinctrl.dtsi:1869 */
				bias-pull-up;       /* in modules/hal/stm32/dts/st/f4/stm32f469nihx-pinctrl.dtsi:1870 */
				drive-open-drain;   /* in modules/hal/stm32/dts/st/f4/stm32f469nihx-pinctrl.dtsi:1871 */
				phandle = < 0x7 >;  /* in zephyr/boards/st/stm32f469i_disco/stm32f469i_disco.dts:135 */
			};

			/* node '/soc/pin-controller@40020000/i2c1_sda_pb9' defined in modules/hal/stm32/dts/st/f4/stm32f469nihx-pinctrl.dtsi:1912 */
			i2c1_sda_pb9: i2c1_sda_pb9 {
				pinmux = < 0x324 >; /* in modules/hal/stm32/dts/st/f4/stm32f469nihx-pinctrl.dtsi:1913 */
				bias-pull-up;       /* in modules/hal/stm32/dts/st/f4/stm32f469nihx-pinctrl.dtsi:1914 */
				drive-open-drain;   /* in modules/hal/stm32/dts/st/f4/stm32f469nihx-pinctrl.dtsi:1915 */
				phandle = < 0x8 >;  /* in zephyr/boards/st/stm32f469i_disco/stm32f469i_disco.dts:135 */
			};

			/* node '/soc/pin-controller@40020000/sdio_d0_pc8' defined in modules/hal/stm32/dts/st/f4/stm32f469nihx-pinctrl.dtsi:2675 */
			sdio_d0_pc8: sdio_d0_pc8 {
				pinmux = < 0x50c >;            /* in modules/hal/stm32/dts/st/f4/stm32f469nihx-pinctrl.dtsi:2676 */
				bias-pull-up;                  /* in modules/hal/stm32/dts/st/f4/stm32f469nihx-pinctrl.dtsi:2677 */
				slew-rate = "very-high-speed"; /* in modules/hal/stm32/dts/st/f4/stm32f469nihx-pinctrl.dtsi:2678 */
				phandle = < 0xd >;             /* in zephyr/boards/st/stm32f469i_disco/stm32f469i_disco.dts:170 */
			};

			/* node '/soc/pin-controller@40020000/sdio_d1_pc9' defined in modules/hal/stm32/dts/st/f4/stm32f469nihx-pinctrl.dtsi:2681 */
			sdio_d1_pc9: sdio_d1_pc9 {
				pinmux = < 0x52c >;            /* in modules/hal/stm32/dts/st/f4/stm32f469nihx-pinctrl.dtsi:2682 */
				bias-pull-up;                  /* in modules/hal/stm32/dts/st/f4/stm32f469nihx-pinctrl.dtsi:2683 */
				slew-rate = "very-high-speed"; /* in modules/hal/stm32/dts/st/f4/stm32f469nihx-pinctrl.dtsi:2684 */
				phandle = < 0xe >;             /* in zephyr/boards/st/stm32f469i_disco/stm32f469i_disco.dts:170 */
			};

			/* node '/soc/pin-controller@40020000/sdio_d2_pc10' defined in modules/hal/stm32/dts/st/f4/stm32f469nihx-pinctrl.dtsi:2687 */
			sdio_d2_pc10: sdio_d2_pc10 {
				pinmux = < 0x54c >;            /* in modules/hal/stm32/dts/st/f4/stm32f469nihx-pinctrl.dtsi:2688 */
				bias-pull-up;                  /* in modules/hal/stm32/dts/st/f4/stm32f469nihx-pinctrl.dtsi:2689 */
				slew-rate = "very-high-speed"; /* in modules/hal/stm32/dts/st/f4/stm32f469nihx-pinctrl.dtsi:2690 */
				phandle = < 0xf >;             /* in zephyr/boards/st/stm32f469i_disco/stm32f469i_disco.dts:170 */
			};

			/* node '/soc/pin-controller@40020000/sdio_d3_pc11' defined in modules/hal/stm32/dts/st/f4/stm32f469nihx-pinctrl.dtsi:2693 */
			sdio_d3_pc11: sdio_d3_pc11 {
				pinmux = < 0x56c >;            /* in modules/hal/stm32/dts/st/f4/stm32f469nihx-pinctrl.dtsi:2694 */
				bias-pull-up;                  /* in modules/hal/stm32/dts/st/f4/stm32f469nihx-pinctrl.dtsi:2695 */
				slew-rate = "very-high-speed"; /* in modules/hal/stm32/dts/st/f4/stm32f469nihx-pinctrl.dtsi:2696 */
				phandle = < 0x10 >;            /* in zephyr/boards/st/stm32f469i_disco/stm32f469i_disco.dts:170 */
			};

			/* node '/soc/pin-controller@40020000/sdio_ck_pc12' defined in modules/hal/stm32/dts/st/f4/stm32f469nihx-pinctrl.dtsi:2699 */
			sdio_ck_pc12: sdio_ck_pc12 {
				pinmux = < 0x58c >;            /* in modules/hal/stm32/dts/st/f4/stm32f469nihx-pinctrl.dtsi:2700 */
				bias-pull-up;                  /* in modules/hal/stm32/dts/st/f4/stm32f469nihx-pinctrl.dtsi:2701 */
				slew-rate = "very-high-speed"; /* in modules/hal/stm32/dts/st/f4/stm32f469nihx-pinctrl.dtsi:2702 */
				phandle = < 0x11 >;            /* in zephyr/boards/st/stm32f469i_disco/stm32f469i_disco.dts:170 */
			};

			/* node '/soc/pin-controller@40020000/sdio_cmd_pd2' defined in modules/hal/stm32/dts/st/f4/stm32f469nihx-pinctrl.dtsi:2705 */
			sdio_cmd_pd2: sdio_cmd_pd2 {
				pinmux = < 0x64c >;            /* in modules/hal/stm32/dts/st/f4/stm32f469nihx-pinctrl.dtsi:2706 */
				bias-pull-up;                  /* in modules/hal/stm32/dts/st/f4/stm32f469nihx-pinctrl.dtsi:2707 */
				slew-rate = "very-high-speed"; /* in modules/hal/stm32/dts/st/f4/stm32f469nihx-pinctrl.dtsi:2708 */
				phandle = < 0x12 >;            /* in zephyr/boards/st/stm32f469i_disco/stm32f469i_disco.dts:170 */
			};

			/* node '/soc/pin-controller@40020000/spi2_miso_pb14' defined in modules/hal/stm32/dts/st/f4/stm32f469nihx-pinctrl.dtsi:2723 */
			spi2_miso_pb14: spi2_miso_pb14 {
				pinmux = < 0x3c5 >; /* in modules/hal/stm32/dts/st/f4/stm32f469nihx-pinctrl.dtsi:2724 */
				bias-pull-down;     /* in modules/hal/stm32/dts/st/f4/stm32f469nihx-pinctrl.dtsi:2725 */
				phandle = < 0x15 >; /* in zephyr/boards/st/stm32f469i_disco/stm32f469i_disco.dts:148 */
			};

			/* node '/soc/pin-controller@40020000/spi2_mosi_pb15' defined in modules/hal/stm32/dts/st/f4/stm32f469nihx-pinctrl.dtsi:2785 */
			spi2_mosi_pb15: spi2_mosi_pb15 {
				pinmux = < 0x3e5 >; /* in modules/hal/stm32/dts/st/f4/stm32f469nihx-pinctrl.dtsi:2786 */
				bias-pull-down;     /* in modules/hal/stm32/dts/st/f4/stm32f469nihx-pinctrl.dtsi:2787 */
				phandle = < 0x16 >; /* in zephyr/boards/st/stm32f469i_disco/stm32f469i_disco.dts:148 */
			};

			/* node '/soc/pin-controller@40020000/spi2_sck_pd3' defined in modules/hal/stm32/dts/st/f4/stm32f469nihx-pinctrl.dtsi:2939 */
			spi2_sck_pd3: spi2_sck_pd3 {
				pinmux = < 0x665 >;            /* in modules/hal/stm32/dts/st/f4/stm32f469nihx-pinctrl.dtsi:2940 */
				bias-pull-down;                /* in modules/hal/stm32/dts/st/f4/stm32f469nihx-pinctrl.dtsi:2941 */
				slew-rate = "very-high-speed"; /* in modules/hal/stm32/dts/st/f4/stm32f469nihx-pinctrl.dtsi:2942 */
				phandle = < 0x14 >;            /* in zephyr/boards/st/stm32f469i_disco/stm32f469i_disco.dts:148 */
			};

			/* node '/soc/pin-controller@40020000/usart3_rx_pb11' defined in modules/hal/stm32/dts/st/f4/stm32f469nihx-pinctrl.dtsi:3449 */
			usart3_rx_pb11: usart3_rx_pb11 {
				pinmux = < 0x367 >; /* in modules/hal/stm32/dts/st/f4/stm32f469nihx-pinctrl.dtsi:3450 */
				phandle = < 0x1a >; /* in zephyr/boards/st/stm32f469i_disco/stm32f469i_disco.dts:121 */
			};

			/* node '/soc/pin-controller@40020000/usart6_rx_pg9' defined in modules/hal/stm32/dts/st/f4/stm32f469nihx-pinctrl.dtsi:3477 */
			usart6_rx_pg9: usart6_rx_pg9 {
				pinmux = < 0xd28 >; /* in modules/hal/stm32/dts/st/f4/stm32f469nihx-pinctrl.dtsi:3478 */
				phandle = < 0x6 >;  /* in zephyr/boards/st/stm32f469i_disco/stm32f469i_disco.dts:128 */
			};

			/* node '/soc/pin-controller@40020000/usart3_tx_pb10' defined in modules/hal/stm32/dts/st/f4/stm32f469nihx-pinctrl.dtsi:3515 */
			usart3_tx_pb10: usart3_tx_pb10 {
				pinmux = < 0x347 >; /* in modules/hal/stm32/dts/st/f4/stm32f469nihx-pinctrl.dtsi:3516 */
				bias-pull-up;       /* in modules/hal/stm32/dts/st/f4/stm32f469nihx-pinctrl.dtsi:3517 */
				phandle = < 0x19 >; /* in zephyr/boards/st/stm32f469i_disco/stm32f469i_disco.dts:121 */
			};

			/* node '/soc/pin-controller@40020000/usart6_tx_pg14' defined in modules/hal/stm32/dts/st/f4/stm32f469nihx-pinctrl.dtsi:3550 */
			usart6_tx_pg14: usart6_tx_pg14 {
				pinmux = < 0xdc8 >; /* in modules/hal/stm32/dts/st/f4/stm32f469nihx-pinctrl.dtsi:3551 */
				bias-pull-up;       /* in modules/hal/stm32/dts/st/f4/stm32f469nihx-pinctrl.dtsi:3552 */
				phandle = < 0x5 >;  /* in zephyr/boards/st/stm32f469i_disco/stm32f469i_disco.dts:128 */
			};

			/* node '/soc/pin-controller@40020000/usb_otg_fs_dm_pa11' defined in modules/hal/stm32/dts/st/f4/stm32f469nihx-pinctrl.dtsi:3584 */
			usb_otg_fs_dm_pa11: usb_otg_fs_dm_pa11 {
				pinmux = < 0x16a >; /* in modules/hal/stm32/dts/st/f4/stm32f469nihx-pinctrl.dtsi:3585 */
				phandle = < 0xb >;  /* in zephyr/boards/st/stm32f469i_disco/stm32f469i_disco.dts:155 */
			};

			/* node '/soc/pin-controller@40020000/usb_otg_fs_dp_pa12' defined in modules/hal/stm32/dts/st/f4/stm32f469nihx-pinctrl.dtsi:3588 */
			usb_otg_fs_dp_pa12: usb_otg_fs_dp_pa12 {
				pinmux = < 0x18a >; /* in modules/hal/stm32/dts/st/f4/stm32f469nihx-pinctrl.dtsi:3589 */
				phandle = < 0xc >;  /* in zephyr/boards/st/stm32f469i_disco/stm32f469i_disco.dts:155 */
			};
		};

		/* node '/soc/watchdog@40003000' defined in zephyr/dts/arm/st/f4/stm32f4.dtsi:227 */
		iwdg: watchdog@40003000 {
			compatible = "st,stm32-watchdog"; /* in zephyr/dts/arm/st/f4/stm32f4.dtsi:228 */
			reg = < 0x40003000 0x400 >;       /* in zephyr/dts/arm/st/f4/stm32f4.dtsi:229 */
			status = "disabled";              /* in zephyr/dts/arm/st/f4/stm32f4.dtsi:230 */
		};

		/* node '/soc/watchdog@40002c00' defined in zephyr/dts/arm/st/f4/stm32f4.dtsi:233 */
		wwdg: watchdog@40002c00 {
			compatible = "st,stm32-window-watchdog"; /* in zephyr/dts/arm/st/f4/stm32f4.dtsi:234 */
			reg = < 0x40002c00 0x400 >;              /* in zephyr/dts/arm/st/f4/stm32f4.dtsi:235 */
			clocks = < &rcc 0x40 0x800 >;            /* in zephyr/dts/arm/st/f4/stm32f4.dtsi:236 */
			interrupts = < 0x0 0x7 >;                /* in zephyr/dts/arm/st/f4/stm32f4.dtsi:237 */
			status = "disabled";                     /* in zephyr/dts/arm/st/f4/stm32f4.dtsi:238 */
		};

		/* node '/soc/serial@40011000' defined in zephyr/dts/arm/st/f4/stm32f4.dtsi:241 */
		usart1: serial@40011000 {
			compatible = "st,stm32-usart",
			             "st,stm32-uart";  /* in zephyr/dts/arm/st/f4/stm32f4.dtsi:242 */
			reg = < 0x40011000 0x400 >;    /* in zephyr/dts/arm/st/f4/stm32f4.dtsi:243 */
			clocks = < &rcc 0x44 0x10 >;   /* in zephyr/dts/arm/st/f4/stm32f4.dtsi:244 */
			resets = < &rctl 0x484 >;      /* in zephyr/dts/arm/st/f4/stm32f4.dtsi:245 */
			interrupts = < 0x25 0x0 >;     /* in zephyr/dts/arm/st/f4/stm32f4.dtsi:246 */
			status = "disabled";           /* in zephyr/dts/arm/st/f4/stm32f4.dtsi:247 */
		};

		/* node '/soc/serial@40004400' defined in zephyr/dts/arm/st/f4/stm32f4.dtsi:250 */
		usart2: serial@40004400 {
			compatible = "st,stm32-usart",
			             "st,stm32-uart";   /* in zephyr/dts/arm/st/f4/stm32f4.dtsi:251 */
			reg = < 0x40004400 0x400 >;     /* in zephyr/dts/arm/st/f4/stm32f4.dtsi:252 */
			clocks = < &rcc 0x40 0x20000 >; /* in zephyr/dts/arm/st/f4/stm32f4.dtsi:253 */
			resets = < &rctl 0x411 >;       /* in zephyr/dts/arm/st/f4/stm32f4.dtsi:254 */
			interrupts = < 0x26 0x0 >;      /* in zephyr/dts/arm/st/f4/stm32f4.dtsi:255 */
			status = "disabled";            /* in zephyr/dts/arm/st/f4/stm32f4.dtsi:256 */
		};

		/* node '/soc/serial@40011400' defined in zephyr/dts/arm/st/f4/stm32f4.dtsi:259 */
		usart6: arduino_serial: serial@40011400 {
			compatible = "st,stm32-usart",
			             "st,stm32-uart";                   /* in zephyr/dts/arm/st/f4/stm32f4.dtsi:260 */
			reg = < 0x40011400 0x400 >;                     /* in zephyr/dts/arm/st/f4/stm32f4.dtsi:261 */
			clocks = < &rcc 0x44 0x20 >;                    /* in zephyr/dts/arm/st/f4/stm32f4.dtsi:262 */
			resets = < &rctl 0x485 >;                       /* in zephyr/dts/arm/st/f4/stm32f4.dtsi:263 */
			interrupts = < 0x47 0x0 >;                      /* in zephyr/dts/arm/st/f4/stm32f4.dtsi:264 */
			pinctrl-0 = < &usart6_tx_pg14 &usart6_rx_pg9 >; /* in zephyr/boards/st/stm32f469i_disco/stm32f469i_disco.dts:128 */
			pinctrl-names = "default";                      /* in zephyr/boards/st/stm32f469i_disco/stm32f469i_disco.dts:129 */
			current-speed = < 0x1c200 >;                    /* in zephyr/boards/st/stm32f469i_disco/stm32f469i_disco.dts:130 */
			status = "okay";                                /* in zephyr/boards/st/stm32f469i_disco/stm32f469i_disco.dts:131 */
		};

		/* node '/soc/i2c@40005400' defined in zephyr/dts/arm/st/f4/stm32f4.dtsi:268 */
		i2c1: arduino_i2c: i2c@40005400 {
			compatible = "st,stm32-i2c-v1";              /* in zephyr/dts/arm/st/f4/stm32f4.dtsi:269 */
			clock-frequency = < 0x186a0 >;               /* in zephyr/dts/arm/st/f4/stm32f4.dtsi:270 */
			#address-cells = < 0x1 >;                    /* in zephyr/dts/arm/st/f4/stm32f4.dtsi:271 */
			#size-cells = < 0x0 >;                       /* in zephyr/dts/arm/st/f4/stm32f4.dtsi:272 */
			reg = < 0x40005400 0x400 >;                  /* in zephyr/dts/arm/st/f4/stm32f4.dtsi:273 */
			clocks = < &rcc 0x40 0x200000 >;             /* in zephyr/dts/arm/st/f4/stm32f4.dtsi:274 */
			interrupts = < 0x1f 0x0 >,
			             < 0x20 0x0 >;                   /* in zephyr/dts/arm/st/f4/stm32f4.dtsi:275 */
			interrupt-names = "event",
			                  "error";                   /* in zephyr/dts/arm/st/f4/stm32f4.dtsi:276 */
			pinctrl-0 = < &i2c1_scl_pb8 &i2c1_sda_pb9 >; /* in zephyr/boards/st/stm32f469i_disco/stm32f469i_disco.dts:135 */
			pinctrl-names = "default";                   /* in zephyr/boards/st/stm32f469i_disco/stm32f469i_disco.dts:136 */
			status = "okay";                             /* in zephyr/boards/st/stm32f469i_disco/stm32f469i_disco.dts:137 */
			phandle = < 0x5b >;                          /* in zephyr/dts/arm/st/f4/stm32f4.dtsi:654 */

			/* node '/soc/i2c@40005400/ft5336@2a' defined in zephyr/boards/st/stm32f469i_disco/stm32f469i_disco.dts:139 */
			ft5336: ft5336@2a {
				compatible = "focaltech,ft5336"; /* in zephyr/boards/st/stm32f469i_disco/stm32f469i_disco.dts:140 */
				reg = < 0x2a >;                  /* in zephyr/boards/st/stm32f469i_disco/stm32f469i_disco.dts:141 */
				int-gpios = < &gpioj 0x5 0x0 >;  /* in zephyr/boards/st/stm32f469i_disco/stm32f469i_disco.dts:142 */
				status = "okay";                 /* in zephyr/boards/st/stm32f469i_disco/stm32f469i_disco.dts:143 */
				phandle = < 0x62 >;              /* in zephyr/boards/st/stm32f469i_disco/stm32f469i_disco.dts:60 */
			};
		};

		/* node '/soc/i2c@40005800' defined in zephyr/dts/arm/st/f4/stm32f4.dtsi:280 */
		i2c2: i2c@40005800 {
			compatible = "st,stm32-i2c-v1";  /* in zephyr/dts/arm/st/f4/stm32f4.dtsi:281 */
			clock-frequency = < 0x186a0 >;   /* in zephyr/dts/arm/st/f4/stm32f4.dtsi:282 */
			#address-cells = < 0x1 >;        /* in zephyr/dts/arm/st/f4/stm32f4.dtsi:283 */
			#size-cells = < 0x0 >;           /* in zephyr/dts/arm/st/f4/stm32f4.dtsi:284 */
			reg = < 0x40005800 0x400 >;      /* in zephyr/dts/arm/st/f4/stm32f4.dtsi:285 */
			clocks = < &rcc 0x40 0x400000 >; /* in zephyr/dts/arm/st/f4/stm32f4.dtsi:286 */
			interrupts = < 0x21 0x0 >,
			             < 0x22 0x0 >;       /* in zephyr/dts/arm/st/f4/stm32f4.dtsi:287 */
			interrupt-names = "event",
			                  "error";       /* in zephyr/dts/arm/st/f4/stm32f4.dtsi:288 */
			status = "disabled";             /* in zephyr/dts/arm/st/f4/stm32f4.dtsi:289 */
			phandle = < 0x5c >;              /* in zephyr/dts/arm/st/f4/stm32f4.dtsi:662 */
		};

		/* node '/soc/i2c@40005c00' defined in zephyr/dts/arm/st/f4/stm32f4.dtsi:292 */
		i2c3: i2c@40005c00 {
			compatible = "st,stm32-i2c-v1";  /* in zephyr/dts/arm/st/f4/stm32f4.dtsi:293 */
			clock-frequency = < 0x186a0 >;   /* in zephyr/dts/arm/st/f4/stm32f4.dtsi:294 */
			#address-cells = < 0x1 >;        /* in zephyr/dts/arm/st/f4/stm32f4.dtsi:295 */
			#size-cells = < 0x0 >;           /* in zephyr/dts/arm/st/f4/stm32f4.dtsi:296 */
			reg = < 0x40005c00 0x400 >;      /* in zephyr/dts/arm/st/f4/stm32f4.dtsi:297 */
			clocks = < &rcc 0x40 0x800000 >; /* in zephyr/dts/arm/st/f4/stm32f4.dtsi:298 */
			interrupts = < 0x48 0x0 >,
			             < 0x49 0x0 >;       /* in zephyr/dts/arm/st/f4/stm32f4.dtsi:299 */
			interrupt-names = "event",
			                  "error";       /* in zephyr/dts/arm/st/f4/stm32f4.dtsi:300 */
			status = "disabled";             /* in zephyr/dts/arm/st/f4/stm32f4.dtsi:301 */
			phandle = < 0x5d >;              /* in zephyr/dts/arm/st/f4/stm32f4.dtsi:670 */
		};

		/* node '/soc/spi@40013000' defined in zephyr/dts/arm/st/f4/stm32f4.dtsi:304 */
		spi1: spi@40013000 {
			compatible = "st,stm32-spi";   /* in zephyr/dts/arm/st/f4/stm32f4.dtsi:305 */
			#address-cells = < 0x1 >;      /* in zephyr/dts/arm/st/f4/stm32f4.dtsi:306 */
			#size-cells = < 0x0 >;         /* in zephyr/dts/arm/st/f4/stm32f4.dtsi:307 */
			reg = < 0x40013000 0x400 >;    /* in zephyr/dts/arm/st/f4/stm32f4.dtsi:308 */
			clocks = < &rcc 0x44 0x1000 >; /* in zephyr/dts/arm/st/f4/stm32f4.dtsi:309 */
			interrupts = < 0x23 0x5 >;     /* in zephyr/dts/arm/st/f4/stm32f4.dtsi:310 */
			status = "disabled";           /* in zephyr/dts/arm/st/f4/stm32f4.dtsi:311 */
		};

		/* node '/soc/usb@50000000' defined in zephyr/dts/arm/st/f4/stm32f4.dtsi:314 */
		usbotg_fs: zephyr_udc0: usb@50000000 {
			compatible = "st,stm32-otgfs";                           /* in zephyr/dts/arm/st/f4/stm32f4.dtsi:315 */
			reg = < 0x50000000 0x40000 >;                            /* in zephyr/dts/arm/st/f4/stm32f4.dtsi:316 */
			interrupts = < 0x43 0x0 >;                               /* in zephyr/dts/arm/st/f4/stm32f4.dtsi:317 */
			interrupt-names = "otgfs";                               /* in zephyr/dts/arm/st/f4/stm32f4.dtsi:318 */
			ram-size = < 0x500 >;                                    /* in zephyr/dts/arm/st/f4/stm32f4.dtsi:320 */
			maximum-speed = "full-speed";                            /* in zephyr/dts/arm/st/f4/stm32f4.dtsi:321 */
			phys = < &otgfs_phy >;                                   /* in zephyr/dts/arm/st/f4/stm32f4.dtsi:322 */
			num-bidir-endpoints = < 0x6 >;                           /* in zephyr/dts/arm/st/f4/stm32f469.dtsi:20 */
			clocks = < &rcc 0x34 0x80 >,
			         < &rcc 0x7 0x1b008c >;                          /* in zephyr/dts/arm/st/f4/stm32f469.dtsi:21 */
			pinctrl-0 = < &usb_otg_fs_dm_pa11 &usb_otg_fs_dp_pa12 >; /* in zephyr/boards/st/stm32f469i_disco/stm32f469i_disco.dts:155 */
			pinctrl-names = "default";                               /* in zephyr/boards/st/stm32f469i_disco/stm32f469i_disco.dts:156 */
			status = "okay";                                         /* in zephyr/boards/st/stm32f469i_disco/stm32f469i_disco.dts:157 */
		};

		/* node '/soc/timers@40010000' defined in zephyr/dts/arm/st/f4/stm32f4.dtsi:328 */
		timers1: timers@40010000 {
			compatible = "st,stm32-timers"; /* in zephyr/dts/arm/st/f4/stm32f4.dtsi:329 */
			reg = < 0x40010000 0x400 >;     /* in zephyr/dts/arm/st/f4/stm32f4.dtsi:330 */
			clocks = < &rcc 0x44 0x1 >,
			         < &rcc 0xd 0xff >;     /* in zephyr/dts/arm/st/f4/stm32f4.dtsi:331 */
			resets = < &rctl 0x480 >;       /* in zephyr/dts/arm/st/f4/stm32f4.dtsi:333 */
			interrupts = < 0x18 0x0 >,
			             < 0x19 0x0 >,
			             < 0x1a 0x0 >,
			             < 0x1b 0x0 >;      /* in zephyr/dts/arm/st/f4/stm32f4.dtsi:334 */
			interrupt-names = "brk",
			                  "up",
			                  "trgcom",
			                  "cc";         /* in zephyr/dts/arm/st/f4/stm32f4.dtsi:335 */
			st,prescaler = < 0x0 >;         /* in zephyr/dts/arm/st/f4/stm32f4.dtsi:336 */
			status = "disabled";            /* in zephyr/dts/arm/st/f4/stm32f4.dtsi:337 */

			/* node '/soc/timers@40010000/pwm' defined in zephyr/dts/arm/st/f4/stm32f4.dtsi:339 */
			pwm {
				compatible = "st,stm32-pwm"; /* in zephyr/dts/arm/st/f4/stm32f4.dtsi:340 */
				status = "disabled";         /* in zephyr/dts/arm/st/f4/stm32f4.dtsi:341 */
				#pwm-cells = < 0x3 >;        /* in zephyr/dts/arm/st/f4/stm32f4.dtsi:342 */
			};

			/* node '/soc/timers@40010000/qdec' defined in zephyr/dts/arm/st/f4/stm32f4.dtsi:345 */
			qdec {
				compatible = "st,stm32-qdec";    /* in zephyr/dts/arm/st/f4/stm32f4.dtsi:346 */
				st,input-filter-level = < 0x0 >; /* in zephyr/dts/arm/st/f4/stm32f4.dtsi:347 */
				status = "disabled";             /* in zephyr/dts/arm/st/f4/stm32f4.dtsi:348 */
			};
		};

		/* node '/soc/timers@40000000' defined in zephyr/dts/arm/st/f4/stm32f4.dtsi:352 */
		timers2: timers@40000000 {
			compatible = "st,stm32-timers"; /* in zephyr/dts/arm/st/f4/stm32f4.dtsi:353 */
			reg = < 0x40000000 0x400 >;     /* in zephyr/dts/arm/st/f4/stm32f4.dtsi:354 */
			clocks = < &rcc 0x40 0x1 >,
			         < &rcc 0xc 0xff >;     /* in zephyr/dts/arm/st/f4/stm32f4.dtsi:355 */
			resets = < &rctl 0x400 >;       /* in zephyr/dts/arm/st/f4/stm32f4.dtsi:357 */
			interrupts = < 0x1c 0x0 >;      /* in zephyr/dts/arm/st/f4/stm32f4.dtsi:358 */
			interrupt-names = "global";     /* in zephyr/dts/arm/st/f4/stm32f4.dtsi:359 */
			st,prescaler = < 0x0 >;         /* in zephyr/dts/arm/st/f4/stm32f4.dtsi:360 */
			status = "disabled";            /* in zephyr/dts/arm/st/f4/stm32f4.dtsi:361 */

			/* node '/soc/timers@40000000/pwm' defined in zephyr/dts/arm/st/f4/stm32f4.dtsi:363 */
			pwm {
				compatible = "st,stm32-pwm"; /* in zephyr/dts/arm/st/f4/stm32f4.dtsi:364 */
				status = "disabled";         /* in zephyr/dts/arm/st/f4/stm32f4.dtsi:365 */
				#pwm-cells = < 0x3 >;        /* in zephyr/dts/arm/st/f4/stm32f4.dtsi:366 */
			};

			/* node '/soc/timers@40000000/counter' defined in zephyr/dts/arm/st/f4/stm32f4.dtsi:369 */
			counter {
				compatible = "st,stm32-counter"; /* in zephyr/dts/arm/st/f4/stm32f4.dtsi:370 */
				status = "disabled";             /* in zephyr/dts/arm/st/f4/stm32f4.dtsi:371 */
			};

			/* node '/soc/timers@40000000/qdec' defined in zephyr/dts/arm/st/f4/stm32f4.dtsi:374 */
			qdec {
				compatible = "st,stm32-qdec";    /* in zephyr/dts/arm/st/f4/stm32f4.dtsi:375 */
				st,input-filter-level = < 0x0 >; /* in zephyr/dts/arm/st/f4/stm32f4.dtsi:376 */
				status = "disabled";             /* in zephyr/dts/arm/st/f4/stm32f4.dtsi:377 */
			};
		};

		/* node '/soc/timers@40000400' defined in zephyr/dts/arm/st/f4/stm32f4.dtsi:381 */
		timers3: timers@40000400 {
			compatible = "st,stm32-timers"; /* in zephyr/dts/arm/st/f4/stm32f4.dtsi:382 */
			reg = < 0x40000400 0x400 >;     /* in zephyr/dts/arm/st/f4/stm32f4.dtsi:383 */
			clocks = < &rcc 0x40 0x2 >,
			         < &rcc 0xc 0xff >;     /* in zephyr/dts/arm/st/f4/stm32f4.dtsi:384 */
			resets = < &rctl 0x401 >;       /* in zephyr/dts/arm/st/f4/stm32f4.dtsi:386 */
			interrupts = < 0x1d 0x0 >;      /* in zephyr/dts/arm/st/f4/stm32f4.dtsi:387 */
			interrupt-names = "global";     /* in zephyr/dts/arm/st/f4/stm32f4.dtsi:388 */
			st,prescaler = < 0x0 >;         /* in zephyr/dts/arm/st/f4/stm32f4.dtsi:389 */
			status = "disabled";            /* in zephyr/dts/arm/st/f4/stm32f4.dtsi:390 */

			/* node '/soc/timers@40000400/pwm' defined in zephyr/dts/arm/st/f4/stm32f4.dtsi:392 */
			pwm {
				compatible = "st,stm32-pwm"; /* in zephyr/dts/arm/st/f4/stm32f4.dtsi:393 */
				status = "disabled";         /* in zephyr/dts/arm/st/f4/stm32f4.dtsi:394 */
				#pwm-cells = < 0x3 >;        /* in zephyr/dts/arm/st/f4/stm32f4.dtsi:395 */
			};

			/* node '/soc/timers@40000400/counter' defined in zephyr/dts/arm/st/f4/stm32f4.dtsi:398 */
			counter {
				compatible = "st,stm32-counter"; /* in zephyr/dts/arm/st/f4/stm32f4.dtsi:399 */
				status = "disabled";             /* in zephyr/dts/arm/st/f4/stm32f4.dtsi:400 */
			};

			/* node '/soc/timers@40000400/qdec' defined in zephyr/dts/arm/st/f4/stm32f4.dtsi:403 */
			qdec {
				compatible = "st,stm32-qdec";    /* in zephyr/dts/arm/st/f4/stm32f4.dtsi:404 */
				st,input-filter-level = < 0x0 >; /* in zephyr/dts/arm/st/f4/stm32f4.dtsi:405 */
				status = "disabled";             /* in zephyr/dts/arm/st/f4/stm32f4.dtsi:406 */
			};
		};

		/* node '/soc/timers@40000800' defined in zephyr/dts/arm/st/f4/stm32f4.dtsi:410 */
		timers4: timers@40000800 {
			compatible = "st,stm32-timers"; /* in zephyr/dts/arm/st/f4/stm32f4.dtsi:411 */
			reg = < 0x40000800 0x400 >;     /* in zephyr/dts/arm/st/f4/stm32f4.dtsi:412 */
			clocks = < &rcc 0x40 0x4 >,
			         < &rcc 0xc 0xff >;     /* in zephyr/dts/arm/st/f4/stm32f4.dtsi:413 */
			resets = < &rctl 0x402 >;       /* in zephyr/dts/arm/st/f4/stm32f4.dtsi:415 */
			interrupts = < 0x1e 0x0 >;      /* in zephyr/dts/arm/st/f4/stm32f4.dtsi:416 */
			interrupt-names = "global";     /* in zephyr/dts/arm/st/f4/stm32f4.dtsi:417 */
			st,prescaler = < 0x0 >;         /* in zephyr/dts/arm/st/f4/stm32f4.dtsi:418 */
			status = "disabled";            /* in zephyr/dts/arm/st/f4/stm32f4.dtsi:419 */

			/* node '/soc/timers@40000800/pwm' defined in zephyr/dts/arm/st/f4/stm32f4.dtsi:421 */
			pwm {
				compatible = "st,stm32-pwm"; /* in zephyr/dts/arm/st/f4/stm32f4.dtsi:422 */
				status = "disabled";         /* in zephyr/dts/arm/st/f4/stm32f4.dtsi:423 */
				#pwm-cells = < 0x3 >;        /* in zephyr/dts/arm/st/f4/stm32f4.dtsi:424 */
			};

			/* node '/soc/timers@40000800/counter' defined in zephyr/dts/arm/st/f4/stm32f4.dtsi:427 */
			counter {
				compatible = "st,stm32-counter"; /* in zephyr/dts/arm/st/f4/stm32f4.dtsi:428 */
				status = "disabled";             /* in zephyr/dts/arm/st/f4/stm32f4.dtsi:429 */
			};

			/* node '/soc/timers@40000800/qdec' defined in zephyr/dts/arm/st/f4/stm32f4.dtsi:432 */
			qdec {
				compatible = "st,stm32-qdec";    /* in zephyr/dts/arm/st/f4/stm32f4.dtsi:433 */
				st,input-filter-level = < 0x0 >; /* in zephyr/dts/arm/st/f4/stm32f4.dtsi:434 */
				status = "disabled";             /* in zephyr/dts/arm/st/f4/stm32f4.dtsi:435 */
			};
		};

		/* node '/soc/timers@40000c00' defined in zephyr/dts/arm/st/f4/stm32f4.dtsi:439 */
		timers5: timers@40000c00 {
			compatible = "st,stm32-timers"; /* in zephyr/dts/arm/st/f4/stm32f4.dtsi:440 */
			reg = < 0x40000c00 0x400 >;     /* in zephyr/dts/arm/st/f4/stm32f4.dtsi:441 */
			clocks = < &rcc 0x40 0x8 >,
			         < &rcc 0xc 0xff >;     /* in zephyr/dts/arm/st/f4/stm32f4.dtsi:442 */
			resets = < &rctl 0x403 >;       /* in zephyr/dts/arm/st/f4/stm32f4.dtsi:444 */
			interrupts = < 0x32 0x0 >;      /* in zephyr/dts/arm/st/f4/stm32f4.dtsi:445 */
			interrupt-names = "global";     /* in zephyr/dts/arm/st/f4/stm32f4.dtsi:446 */
			st,prescaler = < 0x0 >;         /* in zephyr/dts/arm/st/f4/stm32f4.dtsi:447 */
			status = "disabled";            /* in zephyr/dts/arm/st/f4/stm32f4.dtsi:448 */

			/* node '/soc/timers@40000c00/pwm' defined in zephyr/dts/arm/st/f4/stm32f4.dtsi:450 */
			pwm {
				compatible = "st,stm32-pwm"; /* in zephyr/dts/arm/st/f4/stm32f4.dtsi:451 */
				status = "disabled";         /* in zephyr/dts/arm/st/f4/stm32f4.dtsi:452 */
				#pwm-cells = < 0x3 >;        /* in zephyr/dts/arm/st/f4/stm32f4.dtsi:453 */
			};

			/* node '/soc/timers@40000c00/counter' defined in zephyr/dts/arm/st/f4/stm32f4.dtsi:456 */
			counter {
				compatible = "st,stm32-counter"; /* in zephyr/dts/arm/st/f4/stm32f4.dtsi:457 */
				status = "disabled";             /* in zephyr/dts/arm/st/f4/stm32f4.dtsi:458 */
			};

			/* node '/soc/timers@40000c00/qdec' defined in zephyr/dts/arm/st/f4/stm32f4.dtsi:461 */
			qdec {
				compatible = "st,stm32-qdec";    /* in zephyr/dts/arm/st/f4/stm32f4.dtsi:462 */
				st,input-filter-level = < 0x0 >; /* in zephyr/dts/arm/st/f4/stm32f4.dtsi:463 */
				status = "disabled";             /* in zephyr/dts/arm/st/f4/stm32f4.dtsi:464 */
			};
		};

		/* node '/soc/timers@40014000' defined in zephyr/dts/arm/st/f4/stm32f4.dtsi:468 */
		timers9: timers@40014000 {
			compatible = "st,stm32-timers"; /* in zephyr/dts/arm/st/f4/stm32f4.dtsi:469 */
			reg = < 0x40014000 0x400 >;     /* in zephyr/dts/arm/st/f4/stm32f4.dtsi:470 */
			clocks = < &rcc 0x44 0x10000 >,
			         < &rcc 0xd 0xff >;     /* in zephyr/dts/arm/st/f4/stm32f4.dtsi:471 */
			resets = < &rctl 0x490 >;       /* in zephyr/dts/arm/st/f4/stm32f4.dtsi:473 */
			interrupts = < 0x18 0x0 >;      /* in zephyr/dts/arm/st/f4/stm32f4.dtsi:474 */
			interrupt-names = "global";     /* in zephyr/dts/arm/st/f4/stm32f4.dtsi:475 */
			st,prescaler = < 0x0 >;         /* in zephyr/dts/arm/st/f4/stm32f4.dtsi:476 */
			status = "disabled";            /* in zephyr/dts/arm/st/f4/stm32f4.dtsi:477 */

			/* node '/soc/timers@40014000/pwm' defined in zephyr/dts/arm/st/f4/stm32f4.dtsi:479 */
			pwm {
				compatible = "st,stm32-pwm"; /* in zephyr/dts/arm/st/f4/stm32f4.dtsi:480 */
				status = "disabled";         /* in zephyr/dts/arm/st/f4/stm32f4.dtsi:481 */
				#pwm-cells = < 0x3 >;        /* in zephyr/dts/arm/st/f4/stm32f4.dtsi:482 */
			};

			/* node '/soc/timers@40014000/counter' defined in zephyr/dts/arm/st/f4/stm32f4.dtsi:485 */
			counter {
				compatible = "st,stm32-counter"; /* in zephyr/dts/arm/st/f4/stm32f4.dtsi:486 */
				status = "disabled";             /* in zephyr/dts/arm/st/f4/stm32f4.dtsi:487 */
			};
		};

		/* node '/soc/timers@40014400' defined in zephyr/dts/arm/st/f4/stm32f4.dtsi:491 */
		timers10: timers@40014400 {
			compatible = "st,stm32-timers"; /* in zephyr/dts/arm/st/f4/stm32f4.dtsi:492 */
			reg = < 0x40014400 0x400 >;     /* in zephyr/dts/arm/st/f4/stm32f4.dtsi:493 */
			clocks = < &rcc 0x44 0x20000 >,
			         < &rcc 0xd 0xff >;     /* in zephyr/dts/arm/st/f4/stm32f4.dtsi:494 */
			resets = < &rctl 0x491 >;       /* in zephyr/dts/arm/st/f4/stm32f4.dtsi:496 */
			interrupts = < 0x19 0x0 >;      /* in zephyr/dts/arm/st/f4/stm32f4.dtsi:497 */
			interrupt-names = "global";     /* in zephyr/dts/arm/st/f4/stm32f4.dtsi:498 */
			st,prescaler = < 0x0 >;         /* in zephyr/dts/arm/st/f4/stm32f4.dtsi:499 */
			status = "disabled";            /* in zephyr/dts/arm/st/f4/stm32f4.dtsi:500 */

			/* node '/soc/timers@40014400/pwm' defined in zephyr/dts/arm/st/f4/stm32f4.dtsi:502 */
			pwm {
				compatible = "st,stm32-pwm"; /* in zephyr/dts/arm/st/f4/stm32f4.dtsi:503 */
				status = "disabled";         /* in zephyr/dts/arm/st/f4/stm32f4.dtsi:504 */
				#pwm-cells = < 0x3 >;        /* in zephyr/dts/arm/st/f4/stm32f4.dtsi:505 */
			};

			/* node '/soc/timers@40014400/counter' defined in zephyr/dts/arm/st/f4/stm32f4.dtsi:508 */
			counter {
				compatible = "st,stm32-counter"; /* in zephyr/dts/arm/st/f4/stm32f4.dtsi:509 */
				status = "disabled";             /* in zephyr/dts/arm/st/f4/stm32f4.dtsi:510 */
			};
		};

		/* node '/soc/timers@40014800' defined in zephyr/dts/arm/st/f4/stm32f4.dtsi:514 */
		timers11: timers@40014800 {
			compatible = "st,stm32-timers"; /* in zephyr/dts/arm/st/f4/stm32f4.dtsi:515 */
			reg = < 0x40014800 0x400 >;     /* in zephyr/dts/arm/st/f4/stm32f4.dtsi:516 */
			clocks = < &rcc 0x44 0x40000 >,
			         < &rcc 0xd 0xff >;     /* in zephyr/dts/arm/st/f4/stm32f4.dtsi:517 */
			resets = < &rctl 0x492 >;       /* in zephyr/dts/arm/st/f4/stm32f4.dtsi:519 */
			interrupts = < 0x1a 0x0 >;      /* in zephyr/dts/arm/st/f4/stm32f4.dtsi:520 */
			interrupt-names = "global";     /* in zephyr/dts/arm/st/f4/stm32f4.dtsi:521 */
			st,prescaler = < 0x0 >;         /* in zephyr/dts/arm/st/f4/stm32f4.dtsi:522 */
			status = "disabled";            /* in zephyr/dts/arm/st/f4/stm32f4.dtsi:523 */

			/* node '/soc/timers@40014800/pwm' defined in zephyr/dts/arm/st/f4/stm32f4.dtsi:525 */
			pwm {
				compatible = "st,stm32-pwm"; /* in zephyr/dts/arm/st/f4/stm32f4.dtsi:526 */
				status = "disabled";         /* in zephyr/dts/arm/st/f4/stm32f4.dtsi:527 */
				#pwm-cells = < 0x3 >;        /* in zephyr/dts/arm/st/f4/stm32f4.dtsi:528 */
			};

			/* node '/soc/timers@40014800/counter' defined in zephyr/dts/arm/st/f4/stm32f4.dtsi:531 */
			counter {
				compatible = "st,stm32-counter"; /* in zephyr/dts/arm/st/f4/stm32f4.dtsi:532 */
				status = "disabled";             /* in zephyr/dts/arm/st/f4/stm32f4.dtsi:533 */
			};
		};

		/* node '/soc/rtc@40002800' defined in zephyr/dts/arm/st/f4/stm32f4.dtsi:537 */
		rtc: rtc@40002800 {
			compatible = "st,stm32-rtc";       /* in zephyr/dts/arm/st/f4/stm32f4.dtsi:538 */
			reg = < 0x40002800 0x400 >;        /* in zephyr/dts/arm/st/f4/stm32f4.dtsi:539 */
			interrupts = < 0x29 0x0 >;         /* in zephyr/dts/arm/st/f4/stm32f4.dtsi:540 */
			prescaler = < 0x8000 >;            /* in zephyr/dts/arm/st/f4/stm32f4.dtsi:542 */
			alarms-count = < 0x2 >;            /* in zephyr/dts/arm/st/f4/stm32f4.dtsi:543 */
			alrm-exti-line = < 0x11 >;         /* in zephyr/dts/arm/st/f4/stm32f4.dtsi:544 */
			clocks = < &rcc 0x40 0x10000000 >,
			         < &rcc 0x3 0x2280070 >;   /* in zephyr/boards/st/stm32f469i_disco/stm32f469i_disco.dts:161 */
			status = "okay";                   /* in zephyr/boards/st/stm32f469i_disco/stm32f469i_disco.dts:163 */

			/* node '/soc/rtc@40002800/backup_regs' defined in zephyr/dts/arm/st/f4/stm32f4.dtsi:547 */
			bbram: backup_regs {
				compatible = "st,stm32-bbram"; /* in zephyr/dts/arm/st/f4/stm32f4.dtsi:548 */
				st,backup-regs = < 0x14 >;     /* in zephyr/dts/arm/st/f4/stm32f4.dtsi:549 */
				status = "disabled";           /* in zephyr/dts/arm/st/f4/stm32f4.dtsi:550 */
			};
		};

		/* node '/soc/adc@40012000' defined in zephyr/dts/arm/st/f4/stm32f4.dtsi:554 */
		adc1: adc@40012000 {
			compatible = "st,stm32f4-adc",
			             "st,stm32-adc";                                 /* in zephyr/dts/arm/st/f4/stm32f4.dtsi:555 */
			reg = < 0x40012000 0x400 >;                                  /* in zephyr/dts/arm/st/f4/stm32f4.dtsi:556 */
			clocks = < &rcc 0x44 0x100 >;                                /* in zephyr/dts/arm/st/f4/stm32f4.dtsi:557 */
			clock-names = "adcx";                                        /* in zephyr/dts/arm/st/f4/stm32f4.dtsi:558 */
			interrupts = < 0x12 0x0 >;                                   /* in zephyr/dts/arm/st/f4/stm32f4.dtsi:559 */
			#io-channel-cells = < 0x1 >;                                 /* in zephyr/dts/arm/st/f4/stm32f4.dtsi:560 */
			resolutions = < 0x607804 0x517804 0x427804 0x337804 >;       /* in zephyr/dts/arm/st/f4/stm32f4.dtsi:561 */
			sampling-times = < 0x3 0xf 0x1c 0x38 0x54 0x70 0x90 0x1e0 >; /* in zephyr/dts/arm/st/f4/stm32f4.dtsi:565 */
			st,adc-clock-source = "SYNC";                                /* in zephyr/dts/arm/st/f4/stm32f4.dtsi:566 */
			st,adc-sequencer = "programmable";                           /* in zephyr/dts/arm/st/f4/stm32f4.dtsi:567 */
			st,adc-oversampler = "none";                                 /* in zephyr/dts/arm/st/f4/stm32f4.dtsi:568 */
			st,adc-internal-regulator = "none";                          /* in zephyr/dts/arm/st/f4/stm32f4.dtsi:569 */
			status = "disabled";                                         /* in zephyr/dts/arm/st/f4/stm32f4.dtsi:570 */
			phandle = < 0x5a >;                                          /* in zephyr/dts/arm/st/f4/stm32f427.dtsi:140 */
		};

		/* node '/soc/dma@40026000' defined in zephyr/dts/arm/st/f4/stm32f4.dtsi:573 */
		dma1: dma@40026000 {
			compatible = "st,stm32-dma-v1";                                                      /* in zephyr/dts/arm/st/f4/stm32f4.dtsi:574 */
			#dma-cells = < 0x4 >;                                                                /* in zephyr/dts/arm/st/f4/stm32f4.dtsi:575 */
			reg = < 0x40026000 0x400 >;                                                          /* in zephyr/dts/arm/st/f4/stm32f4.dtsi:576 */
			interrupts = < 0xb 0x0 0xc 0x0 0xd 0x0 0xe 0x0 0xf 0x0 0x10 0x0 0x11 0x0 0x2f 0x0 >; /* in zephyr/dts/arm/st/f4/stm32f4.dtsi:577 */
			clocks = < &rcc 0x30 0x200000 >;                                                     /* in zephyr/dts/arm/st/f4/stm32f4.dtsi:578 */
			status = "disabled";                                                                 /* in zephyr/dts/arm/st/f4/stm32f4.dtsi:579 */
			phandle = < 0x18 >;                                                                  /* in zephyr/dts/arm/st/f4/stm32f401.dtsi:58 */
		};

		/* node '/soc/dma@40026400' defined in zephyr/dts/arm/st/f4/stm32f4.dtsi:582 */
		dma2: dma@40026400 {
			compatible = "st,stm32-dma-v1";                                                           /* in zephyr/dts/arm/st/f4/stm32f4.dtsi:583 */
			#dma-cells = < 0x4 >;                                                                     /* in zephyr/dts/arm/st/f4/stm32f4.dtsi:584 */
			reg = < 0x40026400 0x400 >;                                                               /* in zephyr/dts/arm/st/f4/stm32f4.dtsi:585 */
			interrupts = < 0x38 0x0 0x39 0x0 0x3a 0x0 0x3b 0x0 0x3c 0x0 0x44 0x0 0x45 0x0 0x46 0x0 >; /* in zephyr/dts/arm/st/f4/stm32f4.dtsi:586 */
			clocks = < &rcc 0x30 0x400000 >;                                                          /* in zephyr/dts/arm/st/f4/stm32f4.dtsi:587 */
			st,mem2mem;                                                                               /* in zephyr/dts/arm/st/f4/stm32f4.dtsi:588 */
			status = "disabled";                                                                      /* in zephyr/dts/arm/st/f4/stm32f4.dtsi:589 */
			phandle = < 0x55 >;                                                                       /* in zephyr/dts/arm/st/f4/stm32f427.dtsi:122 */
		};

		/* node '/soc/sdmmc@40012c00' defined in zephyr/dts/arm/st/f4/stm32f4.dtsi:592 */
		sdmmc1: sdmmc@40012c00 {
			compatible = "st,stm32-sdmmc";                                                                     /* in zephyr/dts/arm/st/f4/stm32f4.dtsi:593 */
			reg = < 0x40012c00 0x400 >;                                                                        /* in zephyr/dts/arm/st/f4/stm32f4.dtsi:594 */
			resets = < &rctl 0x48b >;                                                                          /* in zephyr/dts/arm/st/f4/stm32f4.dtsi:597 */
			interrupts = < 0x31 0x0 >;                                                                         /* in zephyr/dts/arm/st/f4/stm32f4.dtsi:598 */
			clocks = < &rcc 0x44 0x800 >,
			         < &rcc 0x7 0x1b008c >;                                                                    /* in zephyr/boards/st/stm32f469i_disco/stm32f469i_disco.dts:167 */
			status = "okay";                                                                                   /* in zephyr/boards/st/stm32f469i_disco/stm32f469i_disco.dts:169 */
			pinctrl-0 = < &sdio_d0_pc8 &sdio_d1_pc9 &sdio_d2_pc10 &sdio_d3_pc11 &sdio_ck_pc12 &sdio_cmd_pd2 >; /* in zephyr/boards/st/stm32f469i_disco/stm32f469i_disco.dts:170 */
			pinctrl-names = "default";                                                                         /* in zephyr/boards/st/stm32f469i_disco/stm32f469i_disco.dts:176 */
			cd-gpios = < &gpiog 0x2 0x1 >;                                                                     /* in zephyr/boards/st/stm32f469i_disco/stm32f469i_disco.dts:177 */
			disk-name = "SD";                                                                                  /* in zephyr/boards/st/stm32f469i_disco/stm32f469i_disco.dts:178 */
		};

		/* node '/soc/spi@40003800' defined in zephyr/dts/arm/st/f4/stm32f401.dtsi:21 */
		spi2: arduino_spi: spi@40003800 {
			compatible = "st,stm32-spi";                                   /* in zephyr/dts/arm/st/f4/stm32f401.dtsi:22 */
			#address-cells = < 0x1 >;                                      /* in zephyr/dts/arm/st/f4/stm32f401.dtsi:23 */
			#size-cells = < 0x0 >;                                         /* in zephyr/dts/arm/st/f4/stm32f401.dtsi:24 */
			reg = < 0x40003800 0x400 >;                                    /* in zephyr/dts/arm/st/f4/stm32f401.dtsi:25 */
			clocks = < &rcc 0x40 0x4000 >;                                 /* in zephyr/dts/arm/st/f4/stm32f401.dtsi:26 */
			interrupts = < 0x24 0x5 >;                                     /* in zephyr/dts/arm/st/f4/stm32f401.dtsi:27 */
			pinctrl-0 = < &spi2_sck_pd3 &spi2_miso_pb14 &spi2_mosi_pb15 >; /* in zephyr/boards/st/stm32f469i_disco/stm32f469i_disco.dts:148 */
			pinctrl-names = "default";                                     /* in zephyr/boards/st/stm32f469i_disco/stm32f469i_disco.dts:149 */
			cs-gpios = < &gpioh 0x6 0x11 >;                                /* in zephyr/boards/st/stm32f469i_disco/stm32f469i_disco.dts:150 */
			status = "okay";                                               /* in zephyr/boards/st/stm32f469i_disco/stm32f469i_disco.dts:151 */
		};

		/* node '/soc/spi@40003c00' defined in zephyr/dts/arm/st/f4/stm32f401.dtsi:31 */
		spi3: spi@40003c00 {
			compatible = "st,stm32-spi";   /* in zephyr/dts/arm/st/f4/stm32f401.dtsi:32 */
			#address-cells = < 0x1 >;      /* in zephyr/dts/arm/st/f4/stm32f401.dtsi:33 */
			#size-cells = < 0x0 >;         /* in zephyr/dts/arm/st/f4/stm32f401.dtsi:34 */
			reg = < 0x40003c00 0x400 >;    /* in zephyr/dts/arm/st/f4/stm32f401.dtsi:35 */
			clocks = < &rcc 0x40 0x8000 >; /* in zephyr/dts/arm/st/f4/stm32f401.dtsi:36 */
			interrupts = < 0x33 0x5 >;     /* in zephyr/dts/arm/st/f4/stm32f401.dtsi:37 */
			status = "disabled";           /* in zephyr/dts/arm/st/f4/stm32f401.dtsi:38 */
		};

		/* node '/soc/spi@40013400' defined in zephyr/dts/arm/st/f4/stm32f401.dtsi:41 */
		spi4: spi@40013400 {
			compatible = "st,stm32-spi";   /* in zephyr/dts/arm/st/f4/stm32f427.dtsi:67 */
			#address-cells = < 0x1 >;      /* in zephyr/dts/arm/st/f4/stm32f427.dtsi:68 */
			#size-cells = < 0x0 >;         /* in zephyr/dts/arm/st/f4/stm32f427.dtsi:69 */
			reg = < 0x40013400 0x400 >;    /* in zephyr/dts/arm/st/f4/stm32f427.dtsi:70 */
			clocks = < &rcc 0x44 0x2000 >; /* in zephyr/dts/arm/st/f4/stm32f427.dtsi:71 */
			interrupts = < 0x54 0x5 >;     /* in zephyr/dts/arm/st/f4/stm32f427.dtsi:72 */
			status = "disabled";           /* in zephyr/dts/arm/st/f4/stm32f427.dtsi:73 */
		};

		/* node '/soc/i2s@40003800' defined in zephyr/dts/arm/st/f4/stm32f401.dtsi:51 */
		i2s2: i2s@40003800 {
			compatible = "st,stm32-i2s";        /* in zephyr/dts/arm/st/f4/stm32f401.dtsi:52 */
			#address-cells = < 0x1 >;           /* in zephyr/dts/arm/st/f4/stm32f401.dtsi:53 */
			#size-cells = < 0x0 >;              /* in zephyr/dts/arm/st/f4/stm32f401.dtsi:54 */
			reg = < 0x40003800 0x400 >;         /* in zephyr/dts/arm/st/f4/stm32f401.dtsi:55 */
			clocks = < &rcc 0x40 0x4000 >;      /* in zephyr/dts/arm/st/f4/stm32f401.dtsi:56 */
			interrupts = < 0x24 0x5 >;          /* in zephyr/dts/arm/st/f4/stm32f401.dtsi:57 */
			dmas = < &dma1 0x4 0x0 0x400 0x3 >,
			       < &dma1 0x3 0x0 0x400 0x3 >; /* in zephyr/dts/arm/st/f4/stm32f401.dtsi:58 */
			dma-names = "tx",
			            "rx";                   /* in zephyr/dts/arm/st/f4/stm32f401.dtsi:60 */
			status = "disabled";                /* in zephyr/dts/arm/st/f4/stm32f401.dtsi:61 */
		};

		/* node '/soc/i2s@40003c00' defined in zephyr/dts/arm/st/f4/stm32f401.dtsi:64 */
		i2s3: i2s@40003c00 {
			compatible = "st,stm32-i2s";        /* in zephyr/dts/arm/st/f4/stm32f401.dtsi:65 */
			#address-cells = < 0x1 >;           /* in zephyr/dts/arm/st/f4/stm32f401.dtsi:66 */
			#size-cells = < 0x0 >;              /* in zephyr/dts/arm/st/f4/stm32f401.dtsi:67 */
			reg = < 0x40003c00 0x400 >;         /* in zephyr/dts/arm/st/f4/stm32f401.dtsi:68 */
			clocks = < &rcc 0x40 0x8000 >;      /* in zephyr/dts/arm/st/f4/stm32f401.dtsi:69 */
			interrupts = < 0x33 0x5 >;          /* in zephyr/dts/arm/st/f4/stm32f401.dtsi:70 */
			dmas = < &dma1 0x5 0x0 0x400 0x3 >,
			       < &dma1 0x0 0x0 0x400 0x3 >; /* in zephyr/dts/arm/st/f4/stm32f401.dtsi:71 */
			dma-names = "tx",
			            "rx";                   /* in zephyr/dts/arm/st/f4/stm32f401.dtsi:73 */
			status = "disabled";                /* in zephyr/dts/arm/st/f4/stm32f401.dtsi:74 */
		};

		/* node '/soc/serial@40004800' defined in zephyr/dts/arm/st/f4/stm32f405.dtsi:51 */
		usart3: serial@40004800 {
			compatible = "st,stm32-usart",
			             "st,stm32-uart";                    /* in zephyr/dts/arm/st/f4/stm32f405.dtsi:52 */
			reg = < 0x40004800 0x400 >;                      /* in zephyr/dts/arm/st/f4/stm32f405.dtsi:53 */
			clocks = < &rcc 0x40 0x40000 >;                  /* in zephyr/dts/arm/st/f4/stm32f405.dtsi:54 */
			resets = < &rctl 0x412 >;                        /* in zephyr/dts/arm/st/f4/stm32f405.dtsi:55 */
			interrupts = < 0x27 0x0 >;                       /* in zephyr/dts/arm/st/f4/stm32f405.dtsi:56 */
			pinctrl-0 = < &usart3_tx_pb10 &usart3_rx_pb11 >; /* in zephyr/boards/st/stm32f469i_disco/stm32f469i_disco.dts:121 */
			pinctrl-names = "default";                       /* in zephyr/boards/st/stm32f469i_disco/stm32f469i_disco.dts:122 */
			current-speed = < 0x1c200 >;                     /* in zephyr/boards/st/stm32f469i_disco/stm32f469i_disco.dts:123 */
			status = "okay";                                 /* in zephyr/boards/st/stm32f469i_disco/stm32f469i_disco.dts:124 */
		};

		/* node '/soc/serial@40004c00' defined in zephyr/dts/arm/st/f4/stm32f405.dtsi:60 */
		uart4: serial@40004c00 {
			compatible = "st,stm32-uart";   /* in zephyr/dts/arm/st/f4/stm32f405.dtsi:61 */
			reg = < 0x40004c00 0x400 >;     /* in zephyr/dts/arm/st/f4/stm32f405.dtsi:62 */
			clocks = < &rcc 0x40 0x80000 >; /* in zephyr/dts/arm/st/f4/stm32f405.dtsi:63 */
			resets = < &rctl 0x413 >;       /* in zephyr/dts/arm/st/f4/stm32f405.dtsi:64 */
			interrupts = < 0x34 0x0 >;      /* in zephyr/dts/arm/st/f4/stm32f405.dtsi:65 */
			status = "disabled";            /* in zephyr/dts/arm/st/f4/stm32f405.dtsi:66 */
		};

		/* node '/soc/serial@40005000' defined in zephyr/dts/arm/st/f4/stm32f405.dtsi:69 */
		uart5: serial@40005000 {
			compatible = "st,stm32-uart";    /* in zephyr/dts/arm/st/f4/stm32f405.dtsi:70 */
			reg = < 0x40005000 0x400 >;      /* in zephyr/dts/arm/st/f4/stm32f405.dtsi:71 */
			clocks = < &rcc 0x40 0x100000 >; /* in zephyr/dts/arm/st/f4/stm32f405.dtsi:72 */
			resets = < &rctl 0x414 >;        /* in zephyr/dts/arm/st/f4/stm32f405.dtsi:73 */
			interrupts = < 0x35 0x0 >;       /* in zephyr/dts/arm/st/f4/stm32f405.dtsi:74 */
			status = "disabled";             /* in zephyr/dts/arm/st/f4/stm32f405.dtsi:75 */
		};

		/* node '/soc/timers@40001000' defined in zephyr/dts/arm/st/f4/stm32f405.dtsi:78 */
		timers6: timers@40001000 {
			compatible = "st,stm32-timers"; /* in zephyr/dts/arm/st/f4/stm32f405.dtsi:79 */
			reg = < 0x40001000 0x400 >;     /* in zephyr/dts/arm/st/f4/stm32f405.dtsi:80 */
			clocks = < &rcc 0x40 0x10 >,
			         < &rcc 0xc 0xff >;     /* in zephyr/dts/arm/st/f4/stm32f405.dtsi:81 */
			resets = < &rctl 0x404 >;       /* in zephyr/dts/arm/st/f4/stm32f405.dtsi:83 */
			interrupts = < 0x36 0x0 >;      /* in zephyr/dts/arm/st/f4/stm32f405.dtsi:84 */
			interrupt-names = "global";     /* in zephyr/dts/arm/st/f4/stm32f405.dtsi:85 */
			st,prescaler = < 0x0 >;         /* in zephyr/dts/arm/st/f4/stm32f405.dtsi:86 */
			status = "disabled";            /* in zephyr/dts/arm/st/f4/stm32f405.dtsi:87 */

			/* node '/soc/timers@40001000/counter' defined in zephyr/dts/arm/st/f4/stm32f405.dtsi:89 */
			counter {
				compatible = "st,stm32-counter"; /* in zephyr/dts/arm/st/f4/stm32f405.dtsi:90 */
				status = "disabled";             /* in zephyr/dts/arm/st/f4/stm32f405.dtsi:91 */
			};
		};

		/* node '/soc/timers@40001400' defined in zephyr/dts/arm/st/f4/stm32f405.dtsi:95 */
		timers7: timers@40001400 {
			compatible = "st,stm32-timers"; /* in zephyr/dts/arm/st/f4/stm32f405.dtsi:96 */
			reg = < 0x40001400 0x400 >;     /* in zephyr/dts/arm/st/f4/stm32f405.dtsi:97 */
			clocks = < &rcc 0x40 0x20 >,
			         < &rcc 0xc 0xff >;     /* in zephyr/dts/arm/st/f4/stm32f405.dtsi:98 */
			resets = < &rctl 0x405 >;       /* in zephyr/dts/arm/st/f4/stm32f405.dtsi:100 */
			interrupts = < 0x37 0x0 >;      /* in zephyr/dts/arm/st/f4/stm32f405.dtsi:101 */
			interrupt-names = "global";     /* in zephyr/dts/arm/st/f4/stm32f405.dtsi:102 */
			st,prescaler = < 0x0 >;         /* in zephyr/dts/arm/st/f4/stm32f405.dtsi:103 */
			status = "disabled";            /* in zephyr/dts/arm/st/f4/stm32f405.dtsi:104 */

			/* node '/soc/timers@40001400/counter' defined in zephyr/dts/arm/st/f4/stm32f405.dtsi:106 */
			counter {
				compatible = "st,stm32-counter"; /* in zephyr/dts/arm/st/f4/stm32f405.dtsi:107 */
				status = "disabled";             /* in zephyr/dts/arm/st/f4/stm32f405.dtsi:108 */
			};
		};

		/* node '/soc/timers@40010400' defined in zephyr/dts/arm/st/f4/stm32f405.dtsi:112 */
		timers8: timers@40010400 {
			compatible = "st,stm32-timers"; /* in zephyr/dts/arm/st/f4/stm32f405.dtsi:113 */
			reg = < 0x40010400 0x400 >;     /* in zephyr/dts/arm/st/f4/stm32f405.dtsi:114 */
			clocks = < &rcc 0x44 0x2 >,
			         < &rcc 0xd 0xff >;     /* in zephyr/dts/arm/st/f4/stm32f405.dtsi:115 */
			resets = < &rctl 0x481 >;       /* in zephyr/dts/arm/st/f4/stm32f405.dtsi:117 */
			interrupts = < 0x2b 0x0 >,
			             < 0x2c 0x0 >,
			             < 0x2d 0x0 >,
			             < 0x2e 0x0 >;      /* in zephyr/dts/arm/st/f4/stm32f405.dtsi:118 */
			interrupt-names = "brk",
			                  "up",
			                  "trgcom",
			                  "cc";         /* in zephyr/dts/arm/st/f4/stm32f405.dtsi:119 */
			st,prescaler = < 0x0 >;         /* in zephyr/dts/arm/st/f4/stm32f405.dtsi:120 */
			status = "disabled";            /* in zephyr/dts/arm/st/f4/stm32f405.dtsi:121 */

			/* node '/soc/timers@40010400/pwm' defined in zephyr/dts/arm/st/f4/stm32f405.dtsi:123 */
			pwm {
				compatible = "st,stm32-pwm"; /* in zephyr/dts/arm/st/f4/stm32f405.dtsi:124 */
				status = "disabled";         /* in zephyr/dts/arm/st/f4/stm32f405.dtsi:125 */
				#pwm-cells = < 0x3 >;        /* in zephyr/dts/arm/st/f4/stm32f405.dtsi:126 */
			};

			/* node '/soc/timers@40010400/qdec' defined in zephyr/dts/arm/st/f4/stm32f405.dtsi:129 */
			qdec {
				compatible = "st,stm32-qdec";    /* in zephyr/dts/arm/st/f4/stm32f405.dtsi:130 */
				st,input-filter-level = < 0x0 >; /* in zephyr/dts/arm/st/f4/stm32f405.dtsi:131 */
				status = "disabled";             /* in zephyr/dts/arm/st/f4/stm32f405.dtsi:132 */
			};
		};

		/* node '/soc/timers@40001800' defined in zephyr/dts/arm/st/f4/stm32f405.dtsi:136 */
		timers12: timers@40001800 {
			compatible = "st,stm32-timers"; /* in zephyr/dts/arm/st/f4/stm32f405.dtsi:137 */
			reg = < 0x40001800 0x400 >;     /* in zephyr/dts/arm/st/f4/stm32f405.dtsi:138 */
			clocks = < &rcc 0x40 0x40 >,
			         < &rcc 0xc 0xff >;     /* in zephyr/dts/arm/st/f4/stm32f405.dtsi:139 */
			resets = < &rctl 0x406 >;       /* in zephyr/dts/arm/st/f4/stm32f405.dtsi:141 */
			interrupts = < 0x2b 0x0 >;      /* in zephyr/dts/arm/st/f4/stm32f405.dtsi:142 */
			interrupt-names = "global";     /* in zephyr/dts/arm/st/f4/stm32f405.dtsi:143 */
			st,prescaler = < 0x0 >;         /* in zephyr/dts/arm/st/f4/stm32f405.dtsi:144 */
			status = "disabled";            /* in zephyr/dts/arm/st/f4/stm32f405.dtsi:145 */

			/* node '/soc/timers@40001800/pwm' defined in zephyr/dts/arm/st/f4/stm32f405.dtsi:147 */
			pwm {
				compatible = "st,stm32-pwm"; /* in zephyr/dts/arm/st/f4/stm32f405.dtsi:148 */
				status = "disabled";         /* in zephyr/dts/arm/st/f4/stm32f405.dtsi:149 */
				#pwm-cells = < 0x3 >;        /* in zephyr/dts/arm/st/f4/stm32f405.dtsi:150 */
			};

			/* node '/soc/timers@40001800/counter' defined in zephyr/dts/arm/st/f4/stm32f405.dtsi:153 */
			counter {
				compatible = "st,stm32-counter"; /* in zephyr/dts/arm/st/f4/stm32f405.dtsi:154 */
				status = "disabled";             /* in zephyr/dts/arm/st/f4/stm32f405.dtsi:155 */
			};
		};

		/* node '/soc/timers@40001c00' defined in zephyr/dts/arm/st/f4/stm32f405.dtsi:159 */
		timers13: timers@40001c00 {
			compatible = "st,stm32-timers"; /* in zephyr/dts/arm/st/f4/stm32f405.dtsi:160 */
			reg = < 0x40001c00 0x400 >;     /* in zephyr/dts/arm/st/f4/stm32f405.dtsi:161 */
			clocks = < &rcc 0x40 0x80 >,
			         < &rcc 0xc 0xff >;     /* in zephyr/dts/arm/st/f4/stm32f405.dtsi:162 */
			resets = < &rctl 0x407 >;       /* in zephyr/dts/arm/st/f4/stm32f405.dtsi:164 */
			interrupts = < 0x2c 0x0 >;      /* in zephyr/dts/arm/st/f4/stm32f405.dtsi:165 */
			interrupt-names = "global";     /* in zephyr/dts/arm/st/f4/stm32f405.dtsi:166 */
			st,prescaler = < 0x0 >;         /* in zephyr/dts/arm/st/f4/stm32f405.dtsi:167 */
			status = "disabled";            /* in zephyr/dts/arm/st/f4/stm32f405.dtsi:168 */

			/* node '/soc/timers@40001c00/pwm' defined in zephyr/dts/arm/st/f4/stm32f405.dtsi:170 */
			pwm {
				compatible = "st,stm32-pwm"; /* in zephyr/dts/arm/st/f4/stm32f405.dtsi:171 */
				status = "disabled";         /* in zephyr/dts/arm/st/f4/stm32f405.dtsi:172 */
				#pwm-cells = < 0x3 >;        /* in zephyr/dts/arm/st/f4/stm32f405.dtsi:173 */
			};

			/* node '/soc/timers@40001c00/counter' defined in zephyr/dts/arm/st/f4/stm32f405.dtsi:176 */
			counter {
				compatible = "st,stm32-counter"; /* in zephyr/dts/arm/st/f4/stm32f405.dtsi:177 */
				status = "disabled";             /* in zephyr/dts/arm/st/f4/stm32f405.dtsi:178 */
			};
		};

		/* node '/soc/timers@40002000' defined in zephyr/dts/arm/st/f4/stm32f405.dtsi:182 */
		timers14: timers@40002000 {
			compatible = "st,stm32-timers"; /* in zephyr/dts/arm/st/f4/stm32f405.dtsi:183 */
			reg = < 0x40002000 0x400 >;     /* in zephyr/dts/arm/st/f4/stm32f405.dtsi:184 */
			clocks = < &rcc 0x40 0x100 >,
			         < &rcc 0xc 0xff >;     /* in zephyr/dts/arm/st/f4/stm32f405.dtsi:185 */
			resets = < &rctl 0x408 >;       /* in zephyr/dts/arm/st/f4/stm32f405.dtsi:187 */
			interrupts = < 0x2d 0x0 >;      /* in zephyr/dts/arm/st/f4/stm32f405.dtsi:188 */
			interrupt-names = "global";     /* in zephyr/dts/arm/st/f4/stm32f405.dtsi:189 */
			st,prescaler = < 0x0 >;         /* in zephyr/dts/arm/st/f4/stm32f405.dtsi:190 */
			status = "disabled";            /* in zephyr/dts/arm/st/f4/stm32f405.dtsi:191 */

			/* node '/soc/timers@40002000/pwm' defined in zephyr/dts/arm/st/f4/stm32f405.dtsi:193 */
			pwm {
				compatible = "st,stm32-pwm"; /* in zephyr/dts/arm/st/f4/stm32f405.dtsi:194 */
				status = "disabled";         /* in zephyr/dts/arm/st/f4/stm32f405.dtsi:195 */
				#pwm-cells = < 0x3 >;        /* in zephyr/dts/arm/st/f4/stm32f405.dtsi:196 */
			};

			/* node '/soc/timers@40002000/counter' defined in zephyr/dts/arm/st/f4/stm32f405.dtsi:199 */
			counter {
				compatible = "st,stm32-counter"; /* in zephyr/dts/arm/st/f4/stm32f405.dtsi:200 */
				status = "disabled";             /* in zephyr/dts/arm/st/f4/stm32f405.dtsi:201 */
			};
		};

		/* node '/soc/usb@40040000' defined in zephyr/dts/arm/st/f4/stm32f405.dtsi:205 */
		usbotg_hs: usb@40040000 {
			compatible = "st,stm32-otghs";     /* in zephyr/dts/arm/st/f4/stm32f405.dtsi:206 */
			reg = < 0x40040000 0x40000 >;      /* in zephyr/dts/arm/st/f4/stm32f405.dtsi:207 */
			interrupts = < 0x4d 0x0 >,
			             < 0x4a 0x0 >,
			             < 0x4b 0x0 >;         /* in zephyr/dts/arm/st/f4/stm32f405.dtsi:208 */
			interrupt-names = "otghs",
			                  "ep1_out",
			                  "ep1_in";        /* in zephyr/dts/arm/st/f4/stm32f405.dtsi:209 */
			ram-size = < 0x1000 >;             /* in zephyr/dts/arm/st/f4/stm32f405.dtsi:211 */
			maximum-speed = "full-speed";      /* in zephyr/dts/arm/st/f4/stm32f405.dtsi:212 */
			phys = < &otghs_fs_phy >;          /* in zephyr/dts/arm/st/f4/stm32f405.dtsi:213 */
			clocks = < &rcc 0x30 0x20000000 >,
			         < &rcc 0x7 0xff >;        /* in zephyr/dts/arm/st/f4/stm32f405.dtsi:214 */
			status = "disabled";               /* in zephyr/dts/arm/st/f4/stm32f405.dtsi:216 */
			num-bidir-endpoints = < 0x9 >;     /* in zephyr/dts/arm/st/f4/stm32f469.dtsi:26 */
		};

		/* node '/soc/can@40006400' defined in zephyr/dts/arm/st/f4/stm32f405.dtsi:219 */
		can1: can@40006400 {
			compatible = "st,stm32-bxcan";    /* in zephyr/dts/arm/st/f4/stm32f405.dtsi:220 */
			reg = < 0x40006400 0x400 >;       /* in zephyr/dts/arm/st/f4/stm32f405.dtsi:221 */
			interrupts = < 0x13 0x0 >,
			             < 0x14 0x0 >,
			             < 0x15 0x0 >,
			             < 0x16 0x0 >;        /* in zephyr/dts/arm/st/f4/stm32f405.dtsi:222 */
			interrupt-names = "TX",
			                  "RX0",
			                  "RX1",
			                  "SCE";          /* in zephyr/dts/arm/st/f4/stm32f405.dtsi:223 */
			clocks = < &rcc 0x40 0x2000000 >; /* in zephyr/dts/arm/st/f4/stm32f405.dtsi:224 */
			status = "disabled";              /* in zephyr/dts/arm/st/f4/stm32f405.dtsi:225 */
		};

		/* node '/soc/can@40006800' defined in zephyr/dts/arm/st/f4/stm32f405.dtsi:228 */
		can2: can@40006800 {
			compatible = "st,stm32-bxcan";    /* in zephyr/dts/arm/st/f4/stm32f405.dtsi:229 */
			reg = < 0x40006800 0x400 >;       /* in zephyr/dts/arm/st/f4/stm32f405.dtsi:230 */
			interrupts = < 0x3f 0x0 >,
			             < 0x40 0x0 >,
			             < 0x41 0x0 >,
			             < 0x42 0x0 >;        /* in zephyr/dts/arm/st/f4/stm32f405.dtsi:231 */
			interrupt-names = "TX",
			                  "RX0",
			                  "RX1",
			                  "SCE";          /* in zephyr/dts/arm/st/f4/stm32f405.dtsi:232 */
			clocks = < &rcc 0x40 0x6000000 >; /* in zephyr/dts/arm/st/f4/stm32f405.dtsi:234 */
			master-can-reg = < 0x40006400 >;  /* in zephyr/dts/arm/st/f4/stm32f405.dtsi:235 */
			status = "disabled";              /* in zephyr/dts/arm/st/f4/stm32f405.dtsi:236 */
		};

		/* node '/soc/rng@50060800' defined in zephyr/dts/arm/st/f4/stm32f405.dtsi:239 */
		rng: rng@50060800 {
			compatible = "st,stm32-rng"; /* in zephyr/dts/arm/st/f4/stm32f405.dtsi:240 */
			reg = < 0x50060800 0x400 >;  /* in zephyr/dts/arm/st/f4/stm32f405.dtsi:241 */
			interrupts = < 0x50 0x0 >;   /* in zephyr/dts/arm/st/f4/stm32f405.dtsi:242 */
			clocks = < &rcc 0x34 0x40 >; /* in zephyr/dts/arm/st/f4/stm32f405.dtsi:243 */
			status = "disabled";         /* in zephyr/dts/arm/st/f4/stm32f405.dtsi:244 */
		};

		/* node '/soc/memory@40024000' defined in zephyr/dts/arm/st/f4/stm32f405.dtsi:247 */
		backup_sram: memory@40024000 {
			compatible = "zephyr,memory-region",
			             "st,stm32-backup-sram";  /* in zephyr/dts/arm/st/f4/stm32f405.dtsi:248 */
			reg = < 0x40024000 0x1000 >;          /* in zephyr/dts/arm/st/f4/stm32f405.dtsi:249 */
			clocks = < &rcc 0x30 0x40000 >;       /* in zephyr/dts/arm/st/f4/stm32f405.dtsi:250 */
			zephyr,memory-region = "BACKUP_SRAM"; /* in zephyr/dts/arm/st/f4/stm32f405.dtsi:251 */
			status = "disabled";                  /* in zephyr/dts/arm/st/f4/stm32f405.dtsi:252 */
		};

		/* node '/soc/adc@40012100' defined in zephyr/dts/arm/st/f4/stm32f405.dtsi:255 */
		adc2: adc@40012100 {
			compatible = "st,stm32-adc";                                 /* in zephyr/dts/arm/st/f4/stm32f405.dtsi:256 */
			reg = < 0x40012100 0x50 >;                                   /* in zephyr/dts/arm/st/f4/stm32f405.dtsi:257 */
			clocks = < &rcc 0x44 0x200 >;                                /* in zephyr/dts/arm/st/f4/stm32f405.dtsi:258 */
			clock-names = "adcx";                                        /* in zephyr/dts/arm/st/f4/stm32f405.dtsi:259 */
			interrupts = < 0x12 0x0 >;                                   /* in zephyr/dts/arm/st/f4/stm32f405.dtsi:260 */
			#io-channel-cells = < 0x1 >;                                 /* in zephyr/dts/arm/st/f4/stm32f405.dtsi:261 */
			resolutions = < 0x607804 0x517804 0x427804 0x337804 >;       /* in zephyr/dts/arm/st/f4/stm32f405.dtsi:262 */
			sampling-times = < 0x3 0xf 0x1c 0x38 0x54 0x70 0x90 0x1e0 >; /* in zephyr/dts/arm/st/f4/stm32f405.dtsi:266 */
			st,adc-clock-source = "SYNC";                                /* in zephyr/dts/arm/st/f4/stm32f405.dtsi:267 */
			st,adc-sequencer = "programmable";                           /* in zephyr/dts/arm/st/f4/stm32f405.dtsi:268 */
			st,adc-oversampler = "none";                                 /* in zephyr/dts/arm/st/f4/stm32f405.dtsi:269 */
			st,adc-internal-regulator = "none";                          /* in zephyr/dts/arm/st/f4/stm32f405.dtsi:270 */
			status = "disabled";                                         /* in zephyr/dts/arm/st/f4/stm32f405.dtsi:271 */
		};

		/* node '/soc/adc@40012200' defined in zephyr/dts/arm/st/f4/stm32f405.dtsi:274 */
		adc3: adc@40012200 {
			compatible = "st,stm32-adc";                                 /* in zephyr/dts/arm/st/f4/stm32f405.dtsi:275 */
			reg = < 0x40012200 0x50 >;                                   /* in zephyr/dts/arm/st/f4/stm32f405.dtsi:276 */
			clocks = < &rcc 0x44 0x400 >;                                /* in zephyr/dts/arm/st/f4/stm32f405.dtsi:277 */
			clock-names = "adcx";                                        /* in zephyr/dts/arm/st/f4/stm32f405.dtsi:278 */
			interrupts = < 0x12 0x0 >;                                   /* in zephyr/dts/arm/st/f4/stm32f405.dtsi:279 */
			#io-channel-cells = < 0x1 >;                                 /* in zephyr/dts/arm/st/f4/stm32f405.dtsi:280 */
			resolutions = < 0x607804 0x517804 0x427804 0x337804 >;       /* in zephyr/dts/arm/st/f4/stm32f405.dtsi:281 */
			sampling-times = < 0x3 0xf 0x1c 0x38 0x54 0x70 0x90 0x1e0 >; /* in zephyr/dts/arm/st/f4/stm32f405.dtsi:285 */
			st,adc-clock-source = "SYNC";                                /* in zephyr/dts/arm/st/f4/stm32f405.dtsi:286 */
			st,adc-sequencer = "programmable";                           /* in zephyr/dts/arm/st/f4/stm32f405.dtsi:287 */
			st,adc-oversampler = "none";                                 /* in zephyr/dts/arm/st/f4/stm32f405.dtsi:288 */
			st,adc-internal-regulator = "none";                          /* in zephyr/dts/arm/st/f4/stm32f405.dtsi:289 */
			status = "disabled";                                         /* in zephyr/dts/arm/st/f4/stm32f405.dtsi:290 */
		};

		/* node '/soc/dac@40007400' defined in zephyr/dts/arm/st/f4/stm32f405.dtsi:293 */
		dac1: dac@40007400 {
			compatible = "st,stm32-dac";       /* in zephyr/dts/arm/st/f4/stm32f429.dtsi:15 */
			reg = < 0x40007400 0x400 >;        /* in zephyr/dts/arm/st/f4/stm32f429.dtsi:16 */
			clocks = < &rcc 0x40 0x20000000 >; /* in zephyr/dts/arm/st/f4/stm32f429.dtsi:17 */
			status = "disabled";               /* in zephyr/dts/arm/st/f4/stm32f429.dtsi:18 */
			#io-channel-cells = < 0x1 >;       /* in zephyr/dts/arm/st/f4/stm32f429.dtsi:19 */
		};

		/* node '/soc/ethernet@40028000' defined in zephyr/dts/arm/st/f4/stm32f407.dtsi:13 */
		ethernet@40028000 {
			reg = < 0x40028000 0x8000 >;                 /* in zephyr/dts/arm/st/f4/stm32f407.dtsi:14 */
			compatible = "st,stm32-ethernet-controller"; /* in zephyr/dts/arm/st/f4/stm32f407.dtsi:15 */
			clock-names = "stm-eth";                     /* in zephyr/dts/arm/st/f4/stm32f407.dtsi:16 */
			clocks = < &rcc 0x30 0x2000000 >;            /* in zephyr/dts/arm/st/f4/stm32f407.dtsi:17 */

			/* node '/soc/ethernet@40028000/ethernet' defined in zephyr/dts/arm/st/f4/stm32f407.dtsi:19 */
			mac: ethernet {
				compatible = "st,stm32-ethernet";  /* in zephyr/dts/arm/st/f4/stm32f407.dtsi:20 */
				interrupts = < 0x3d 0x0 >;         /* in zephyr/dts/arm/st/f4/stm32f407.dtsi:21 */
				clock-names = "mac-clk-tx",
				              "mac-clk-rx",
				              "mac-clk-ptp";       /* in zephyr/dts/arm/st/f4/stm32f407.dtsi:22 */
				clocks = < &rcc 0x30 0x4000000 >,
				         < &rcc 0x30 0x8000000 >,
				         < &rcc 0x30 0x10000000 >; /* in zephyr/dts/arm/st/f4/stm32f407.dtsi:24 */
				status = "disabled";               /* in zephyr/dts/arm/st/f4/stm32f407.dtsi:27 */
			};

			/* node '/soc/ethernet@40028000/mdio' defined in zephyr/dts/arm/st/f4/stm32f407.dtsi:30 */
			mdio: mdio {
				compatible = "st,stm32-mdio"; /* in zephyr/dts/arm/st/f4/stm32f407.dtsi:31 */
				#address-cells = < 0x1 >;     /* in zephyr/dts/arm/st/f4/stm32f407.dtsi:32 */
				#size-cells = < 0x0 >;        /* in zephyr/dts/arm/st/f4/stm32f407.dtsi:33 */
				status = "disabled";          /* in zephyr/dts/arm/st/f4/stm32f407.dtsi:34 */
			};
		};

		/* node '/soc/serial@40007800' defined in zephyr/dts/arm/st/f4/stm32f427.dtsi:48 */
		uart7: serial@40007800 {
			compatible = "st,stm32-uart";      /* in zephyr/dts/arm/st/f4/stm32f427.dtsi:49 */
			reg = < 0x40007800 0x400 >;        /* in zephyr/dts/arm/st/f4/stm32f427.dtsi:50 */
			clocks = < &rcc 0x40 0x40000000 >; /* in zephyr/dts/arm/st/f4/stm32f427.dtsi:51 */
			resets = < &rctl 0x41e >;          /* in zephyr/dts/arm/st/f4/stm32f427.dtsi:52 */
			interrupts = < 0x52 0x0 >;         /* in zephyr/dts/arm/st/f4/stm32f427.dtsi:53 */
			status = "disabled";               /* in zephyr/dts/arm/st/f4/stm32f427.dtsi:54 */
		};

		/* node '/soc/serial@40007c00' defined in zephyr/dts/arm/st/f4/stm32f427.dtsi:57 */
		uart8: serial@40007c00 {
			compatible = "st,stm32-uart";      /* in zephyr/dts/arm/st/f4/stm32f427.dtsi:58 */
			reg = < 0x40007c00 0x400 >;        /* in zephyr/dts/arm/st/f4/stm32f427.dtsi:59 */
			clocks = < &rcc 0x40 0x80000000 >; /* in zephyr/dts/arm/st/f4/stm32f427.dtsi:60 */
			resets = < &rctl 0x41f >;          /* in zephyr/dts/arm/st/f4/stm32f427.dtsi:61 */
			interrupts = < 0x53 0x0 >;         /* in zephyr/dts/arm/st/f4/stm32f427.dtsi:62 */
			status = "disabled";               /* in zephyr/dts/arm/st/f4/stm32f427.dtsi:63 */
		};

		/* node '/soc/spi@40015000' defined in zephyr/dts/arm/st/f4/stm32f427.dtsi:79 */
		spi5: spi@40015000 {
			compatible = "st,stm32-spi";     /* in zephyr/dts/arm/st/f4/stm32f427.dtsi:80 */
			#address-cells = < 0x1 >;        /* in zephyr/dts/arm/st/f4/stm32f427.dtsi:81 */
			#size-cells = < 0x0 >;           /* in zephyr/dts/arm/st/f4/stm32f427.dtsi:82 */
			reg = < 0x40015000 0x400 >;      /* in zephyr/dts/arm/st/f4/stm32f427.dtsi:83 */
			clocks = < &rcc 0x44 0x100000 >; /* in zephyr/dts/arm/st/f4/stm32f427.dtsi:84 */
			interrupts = < 0x55 0x5 >;       /* in zephyr/dts/arm/st/f4/stm32f427.dtsi:85 */
			status = "disabled";             /* in zephyr/dts/arm/st/f4/stm32f427.dtsi:86 */
		};

		/* node '/soc/spi@40015400' defined in zephyr/dts/arm/st/f4/stm32f427.dtsi:92 */
		spi6: spi@40015400 {
			compatible = "st,stm32-spi";     /* in zephyr/dts/arm/st/f4/stm32f427.dtsi:93 */
			#address-cells = < 0x1 >;        /* in zephyr/dts/arm/st/f4/stm32f427.dtsi:94 */
			#size-cells = < 0x0 >;           /* in zephyr/dts/arm/st/f4/stm32f427.dtsi:95 */
			reg = < 0x40015400 0x400 >;      /* in zephyr/dts/arm/st/f4/stm32f427.dtsi:96 */
			clocks = < &rcc 0x44 0x200000 >; /* in zephyr/dts/arm/st/f4/stm32f427.dtsi:97 */
			interrupts = < 0x56 0x5 >;       /* in zephyr/dts/arm/st/f4/stm32f427.dtsi:98 */
			status = "disabled";             /* in zephyr/dts/arm/st/f4/stm32f427.dtsi:99 */
		};

		/* node '/soc/memory-controller@a0000000' defined in zephyr/dts/arm/st/f4/stm32f427.dtsi:102 */
		fmc: memory-controller@a0000000 {
			compatible = "st,stm32-fmc";                                                                             /* in zephyr/dts/arm/st/f4/stm32f427.dtsi:103 */
			reg = < 0xa0000000 0x400 >;                                                                              /* in zephyr/dts/arm/st/f4/stm32f427.dtsi:104 */
			clocks = < &rcc 0x38 0x1 >;                                                                              /* in zephyr/dts/arm/st/f4/stm32f427.dtsi:105 */
			pinctrl-0 = < &fmc_nbl0_pe0 &fmc_nbl1_pe1 &fmc_nbl2_pi4 &fmc_nbl3_pi5 &fmc_sdclk_pg8 &fmc_sdnwe_pc0
			              &fmc_sdcke0_ph2 &fmc_sdne0_ph3 &fmc_sdnras_pf11 &fmc_sdncas_pg15 &fmc_a0_pf0 &fmc_a1_pf1
			              &fmc_a2_pf2 &fmc_a3_pf3 &fmc_a4_pf4 &fmc_a5_pf5 &fmc_a6_pf12 &fmc_a7_pf13 &fmc_a8_pf14
			              &fmc_a9_pf15 &fmc_a10_pg0 &fmc_a11_pg1 &fmc_a12_pg2 &fmc_a14_pg4 &fmc_a15_pg5 &fmc_d0_pd14
			              &fmc_d1_pd15 &fmc_d2_pd0 &fmc_d3_pd1 &fmc_d4_pe7 &fmc_d5_pe8 &fmc_d6_pe9 &fmc_d7_pe10
			              &fmc_d8_pe11 &fmc_d9_pe12 &fmc_d10_pe13 &fmc_d11_pe14 &fmc_d12_pe15 &fmc_d13_pd8
			              &fmc_d14_pd9 &fmc_d15_pd10 &fmc_d16_ph8 &fmc_d17_ph9 &fmc_d18_ph10 &fmc_d19_ph11
			              &fmc_d20_ph12 &fmc_d21_ph13 &fmc_d22_ph14 &fmc_d23_ph15 &fmc_d24_pi0 &fmc_d25_pi1
			              &fmc_d26_pi2 &fmc_d27_pi3 &fmc_d28_pi6 &fmc_d29_pi7 &fmc_d30_pi9 &fmc_d31_pi10 >;          /* in zephyr/boards/st/stm32f469i_disco/stm32f469i_disco.dts:182 */
			pinctrl-names = "default";                                                                               /* in zephyr/boards/st/stm32f469i_disco/stm32f469i_disco.dts:198 */
			status = "okay";                                                                                         /* in zephyr/boards/st/stm32f469i_disco/stm32f469i_disco.dts:199 */

			/* node '/soc/memory-controller@a0000000/sdram' defined in zephyr/dts/arm/st/f4/stm32f427.dtsi:108 */
			sdram: sdram {
				#address-cells = < 0x1 >;          /* in zephyr/dts/arm/st/f4/stm32f427.dtsi:110 */
				#size-cells = < 0x0 >;             /* in zephyr/dts/arm/st/f4/stm32f427.dtsi:111 */
				compatible = "st,stm32-fmc-sdram"; /* in zephyr/boards/st/stm32f469i_disco/stm32f469i_disco.dts:202 */
				power-up-delay = < 0x64 >;         /* in zephyr/boards/st/stm32f469i_disco/stm32f469i_disco.dts:203 */
				num-auto-refresh = < 0x8 >;        /* in zephyr/boards/st/stm32f469i_disco/stm32f469i_disco.dts:204 */
				mode-register = < 0x230 >;         /* in zephyr/boards/st/stm32f469i_disco/stm32f469i_disco.dts:205 */
				refresh-rate = < 0x50c >;          /* in zephyr/boards/st/stm32f469i_disco/stm32f469i_disco.dts:211 */
				status = "okay";                   /* in zephyr/boards/st/stm32f469i_disco/stm32f469i_disco.dts:212 */

				/* node '/soc/memory-controller@a0000000/sdram/bank@0' defined in zephyr/boards/st/stm32f469i_disco/stm32f469i_disco.dts:214 */
				bank@0 {
					reg = < 0x0 >;                                                   /* in zephyr/boards/st/stm32f469i_disco/stm32f469i_disco.dts:215 */
					st,sdram-control = < 0x0 0x4 0x20 0x40 0x180 0x800 0x1000 0x0 >; /* in zephyr/boards/st/stm32f469i_disco/stm32f469i_disco.dts:216 */
					st,sdram-timing = < 0x2 0x6 0x4 0x6 0x2 0x2 0x2 >;               /* in zephyr/boards/st/stm32f469i_disco/stm32f469i_disco.dts:224 */
				};
			};
		};

		/* node '/soc/sai1@40015804' defined in zephyr/dts/arm/st/f4/stm32f427.dtsi:116 */
		sai1_a: sai1@40015804 {
			compatible = "st,stm32-sai";          /* in zephyr/dts/arm/st/f4/stm32f427.dtsi:117 */
			#address-cells = < 0x1 >;             /* in zephyr/dts/arm/st/f4/stm32f427.dtsi:118 */
			#size-cells = < 0x0 >;                /* in zephyr/dts/arm/st/f4/stm32f427.dtsi:119 */
			reg = < 0x40015804 0x20 >;            /* in zephyr/dts/arm/st/f4/stm32f427.dtsi:120 */
			clocks = < &rcc 0x44 0x400000 >;      /* in zephyr/dts/arm/st/f4/stm32f427.dtsi:121 */
			dmas = < &dma2 0x1 0x0 0x22800 0x0 >; /* in zephyr/dts/arm/st/f4/stm32f427.dtsi:122 */
			status = "disabled";                  /* in zephyr/dts/arm/st/f4/stm32f427.dtsi:124 */
		};

		/* node '/soc/sai1@40015824' defined in zephyr/dts/arm/st/f4/stm32f427.dtsi:127 */
		sai1_b: sai1@40015824 {
			compatible = "st,stm32-sai";          /* in zephyr/dts/arm/st/f4/stm32f427.dtsi:128 */
			#address-cells = < 0x1 >;             /* in zephyr/dts/arm/st/f4/stm32f427.dtsi:129 */
			#size-cells = < 0x0 >;                /* in zephyr/dts/arm/st/f4/stm32f427.dtsi:130 */
			reg = < 0x40015824 0x20 >;            /* in zephyr/dts/arm/st/f4/stm32f427.dtsi:131 */
			clocks = < &rcc 0x44 0x400000 >;      /* in zephyr/dts/arm/st/f4/stm32f427.dtsi:132 */
			dmas = < &dma2 0x5 0x0 0x22800 0x0 >; /* in zephyr/dts/arm/st/f4/stm32f427.dtsi:133 */
			status = "disabled";                  /* in zephyr/dts/arm/st/f4/stm32f427.dtsi:135 */
		};

		/* node '/soc/display-controller@40016800' defined in zephyr/dts/arm/st/f4/stm32f429.dtsi:22 */
		ltdc: display-controller@40016800 {
			compatible = "st,stm32-ltdc";     /* in zephyr/dts/arm/st/f4/stm32f429.dtsi:23 */
			reg = < 0x40016800 0x200 >;       /* in zephyr/dts/arm/st/f4/stm32f429.dtsi:24 */
			interrupts = < 0x58 0x0 >,
			             < 0x59 0x0 >;        /* in zephyr/dts/arm/st/f4/stm32f429.dtsi:25 */
			interrupt-names = "ltdc",
			                  "ltdc_er";      /* in zephyr/dts/arm/st/f4/stm32f429.dtsi:26 */
			clocks = < &rcc 0x44 0x4000000 >; /* in zephyr/dts/arm/st/f4/stm32f429.dtsi:27 */
			resets = < &rctl 0x49a >;         /* in zephyr/dts/arm/st/f4/stm32f429.dtsi:28 */
			width = < 0x320 >;                /* in zephyr/boards/st/stm32f469i_disco/stm32f469i_disco.dts:258 */
			height = < 0x1e0 >;               /* in zephyr/boards/st/stm32f469i_disco/stm32f469i_disco.dts:259 */
			pixel-format = < 0x1 >;           /* in zephyr/boards/st/stm32f469i_disco/stm32f469i_disco.dts:260 */
			ext-sdram = < &sdram1 >;          /* in zephyr/boards/st/stm32f469i_disco/stm32f469i_disco.dts:261 */
			def-back-color-red = < 0x0 >;     /* in zephyr/boards/st/stm32f469i_disco/stm32f469i_disco.dts:262 */
			def-back-color-green = < 0x0 >;   /* in zephyr/boards/st/stm32f469i_disco/stm32f469i_disco.dts:263 */
			def-back-color-blue = < 0x0 >;    /* in zephyr/boards/st/stm32f469i_disco/stm32f469i_disco.dts:264 */
			status = "okay";                  /* in zephyr/boards/st/stm32f469i_disco/stm32f469i_disco.dts:265 */

			/* node '/soc/display-controller@40016800/display-timings' defined in zephyr/boards/st/stm32f469i_disco/stm32f469i_disco.dts:267 */
			display-timings {
				compatible = "zephyr,panel-timing"; /* in zephyr/boards/st/stm32f469i_disco/stm32f469i_disco.dts:268 */
				hsync-active = < 0x0 >;             /* in zephyr/boards/st/stm32f469i_disco/stm32f469i_disco.dts:269 */
				vsync-active = < 0x0 >;             /* in zephyr/boards/st/stm32f469i_disco/stm32f469i_disco.dts:270 */
				de-active = < 0x0 >;                /* in zephyr/boards/st/stm32f469i_disco/stm32f469i_disco.dts:271 */
				pixelclk-active = < 0x0 >;          /* in zephyr/boards/st/stm32f469i_disco/stm32f469i_disco.dts:272 */
				hsync-len = < 0x2 >;                /* in zephyr/boards/st/stm32f469i_disco/stm32f469i_disco.dts:273 */
				vsync-len = < 0x1 >;                /* in zephyr/boards/st/stm32f469i_disco/stm32f469i_disco.dts:274 */
				hback-porch = < 0x22 >;             /* in zephyr/boards/st/stm32f469i_disco/stm32f469i_disco.dts:275 */
				vback-porch = < 0xf >;              /* in zephyr/boards/st/stm32f469i_disco/stm32f469i_disco.dts:276 */
				hfront-porch = < 0x22 >;            /* in zephyr/boards/st/stm32f469i_disco/stm32f469i_disco.dts:277 */
				vfront-porch = < 0x10 >;            /* in zephyr/boards/st/stm32f469i_disco/stm32f469i_disco.dts:278 */
			};
		};

		/* node '/soc/dsihost@40016c00' defined in zephyr/dts/arm/st/f4/stm32f469.dtsi:29 */
		mipi_dsi: dsihost@40016c00 {
			compatible = "st,stm32-mipi-dsi"; /* in zephyr/dts/arm/st/f4/stm32f469.dtsi:30 */
			reg = < 0x40016c00 0x800 >;       /* in zephyr/dts/arm/st/f4/stm32f469.dtsi:31 */
			#address-cells = < 0x1 >;         /* in zephyr/dts/arm/st/f4/stm32f469.dtsi:32 */
			#size-cells = < 0x0 >;            /* in zephyr/dts/arm/st/f4/stm32f469.dtsi:33 */
			clock-names = "dsiclk",
			              "refclk",
			              "pixelclk";         /* in zephyr/dts/arm/st/f4/stm32f469.dtsi:34 */
			clocks = < &rcc 0x44 0x8000000 >,
			         < &rcc 0x5 0xff >,
			         < &rcc 0x12 0xff >;      /* in zephyr/dts/arm/st/f4/stm32f469.dtsi:35 */
			resets = < &rctl 0x49b >;         /* in zephyr/dts/arm/st/f4/stm32f469.dtsi:38 */
			pll-ndiv = < 0x7d >;              /* in zephyr/boards/st/stm32f469i_disco/stm32f469i_disco.dts:235 */
			pll-idf = < 0x2 >;                /* in zephyr/boards/st/stm32f469i_disco/stm32f469i_disco.dts:236 */
			pll-odf = < 0x0 >;                /* in zephyr/boards/st/stm32f469i_disco/stm32f469i_disco.dts:237 */
			vs-active-high;                   /* in zephyr/boards/st/stm32f469i_disco/stm32f469i_disco.dts:238 */
			hs-active-high;                   /* in zephyr/boards/st/stm32f469i_disco/stm32f469i_disco.dts:239 */
			de-active-high;                   /* in zephyr/boards/st/stm32f469i_disco/stm32f469i_disco.dts:240 */
			status = "okay";                  /* in zephyr/boards/st/stm32f469i_disco/stm32f469i_disco.dts:241 */

			/* node '/soc/dsihost@40016c00/otm8009a@0' defined in zephyr/boards/st/stm32f469i_disco/stm32f469i_disco.dts:243 */
			otm8009a: otm8009a@0 {
				compatible = "orisetech,otm8009a"; /* in zephyr/boards/st/stm32f469i_disco/stm32f469i_disco.dts:244 */
				reg = < 0x0 >;                     /* in zephyr/boards/st/stm32f469i_disco/stm32f469i_disco.dts:245 */
				height = < 0x320 >;                /* in zephyr/boards/st/stm32f469i_disco/stm32f469i_disco.dts:246 */
				width = < 0x1e0 >;                 /* in zephyr/boards/st/stm32f469i_disco/stm32f469i_disco.dts:247 */
				reset-gpios = < &gpioh 0x7 0x0 >;  /* in zephyr/boards/st/stm32f469i_disco/stm32f469i_disco.dts:248 */
				bl-gpios = < &gpioa 0x3 0x0 >;     /* in zephyr/boards/st/stm32f469i_disco/stm32f469i_disco.dts:249 */
				data-lanes = < 0x2 >;              /* in zephyr/boards/st/stm32f469i_disco/stm32f469i_disco.dts:250 */
				pixel-format = < 0x0 >;            /* in zephyr/boards/st/stm32f469i_disco/stm32f469i_disco.dts:251 */
				rotation = < 0x5a >;               /* in zephyr/boards/st/stm32f469i_disco/stm32f469i_disco.dts:252 */
				status = "okay";                   /* in zephyr/boards/st/stm32f469i_disco/stm32f469i_disco.dts:253 */
			};
		};
	};

	/* node '/cpus' defined in zephyr/dts/arm/st/f4/stm32f4.dtsi:31 */
	cpus {
		#address-cells = < 0x1 >; /* in zephyr/dts/arm/st/f4/stm32f4.dtsi:32 */
		#size-cells = < 0x0 >;    /* in zephyr/dts/arm/st/f4/stm32f4.dtsi:33 */

		/* node '/cpus/cpu@0' defined in zephyr/dts/arm/st/f4/stm32f4.dtsi:35 */
		cpu0: cpu@0 {
			device_type = "cpu";           /* in zephyr/dts/arm/st/f4/stm32f4.dtsi:36 */
			compatible = "arm,cortex-m4f"; /* in zephyr/dts/arm/st/f4/stm32f4.dtsi:37 */
			reg = < 0x0 >;                 /* in zephyr/dts/arm/st/f4/stm32f4.dtsi:38 */
			cpu-power-states = < &stop >;  /* in zephyr/dts/arm/st/f4/stm32f4.dtsi:39 */
		};

		/* node '/cpus/power-states' defined in zephyr/dts/arm/st/f4/stm32f4.dtsi:42 */
		power-states {

			/* node '/cpus/power-states/stop' defined in zephyr/dts/arm/st/f4/stm32f4.dtsi:43 */
			stop: stop {
				compatible = "zephyr,power-state";    /* in zephyr/dts/arm/st/f4/stm32f4.dtsi:44 */
				power-state-name = "suspend-to-idle"; /* in zephyr/dts/arm/st/f4/stm32f4.dtsi:45 */
				min-residency-us = < 0x190 >;         /* in zephyr/dts/arm/st/f4/stm32f4.dtsi:52 */
				exit-latency-us = < 0x12c >;          /* in zephyr/dts/arm/st/f4/stm32f4.dtsi:53 */
				phandle = < 0x58 >;                   /* in zephyr/dts/arm/st/f4/stm32f4.dtsi:39 */
			};
		};
	};

	/* node '/memory@20000000' defined in zephyr/dts/arm/st/f4/stm32f4.dtsi:58 */
	sram0: memory@20000000 {
		compatible = "zephyr,memory-region",
		             "mmio-sram";            /* in zephyr/dts/arm/st/f4/stm32f4.dtsi:59 */
		zephyr,memory-region = "SRAM0";      /* in zephyr/dts/arm/st/f4/stm32f4.dtsi:60 */
		reg = < 0x20000000 0x50000 >;        /* in zephyr/dts/arm/st/f4/stm32f469Xi.dtsi:17 */
	};

	/* node '/clocks' defined in zephyr/dts/arm/st/f4/stm32f4.dtsi:63 */
	clocks {

		/* node '/clocks/clk-hse' defined in zephyr/dts/arm/st/f4/stm32f4.dtsi:64 */
		clk_hse: clk-hse {
			#clock-cells = < 0x0 >;            /* in zephyr/dts/arm/st/f4/stm32f4.dtsi:65 */
			compatible = "st,stm32-hse-clock"; /* in zephyr/dts/arm/st/f4/stm32f4.dtsi:66 */
			clock-frequency = < 0x7a1200 >;    /* in zephyr/boards/st/stm32f469i_disco/stm32f469i_disco.dts:88 */
			status = "okay";                   /* in zephyr/boards/st/stm32f469i_disco/stm32f469i_disco.dts:89 */
			phandle = < 0x59 >;                /* in zephyr/boards/st/stm32f469i_disco/stm32f469i_disco.dts:98 */
		};

		/* node '/clocks/clk-hsi' defined in zephyr/dts/arm/st/f4/stm32f4.dtsi:70 */
		clk_hsi: clk-hsi {
			#clock-cells = < 0x0 >;         /* in zephyr/dts/arm/st/f4/stm32f4.dtsi:71 */
			compatible = "fixed-clock";     /* in zephyr/dts/arm/st/f4/stm32f4.dtsi:72 */
			clock-frequency = < 0xf42400 >; /* in zephyr/dts/arm/st/f4/stm32f4.dtsi:73 */
			status = "disabled";            /* in zephyr/dts/arm/st/f4/stm32f4.dtsi:74 */
		};

		/* node '/clocks/clk-lse' defined in zephyr/dts/arm/st/f4/stm32f4.dtsi:77 */
		clk_lse: clk-lse {
			#clock-cells = < 0x0 >;       /* in zephyr/dts/arm/st/f4/stm32f4.dtsi:78 */
			compatible = "fixed-clock";   /* in zephyr/dts/arm/st/f4/stm32f4.dtsi:79 */
			clock-frequency = < 0x8000 >; /* in zephyr/dts/arm/st/f4/stm32f4.dtsi:80 */
			status = "disabled";          /* in zephyr/dts/arm/st/f4/stm32f4.dtsi:81 */
		};

		/* node '/clocks/clk-lsi' defined in zephyr/dts/arm/st/f4/stm32f4.dtsi:84 */
		clk_lsi: clk-lsi {
			#clock-cells = < 0x0 >;       /* in zephyr/dts/arm/st/f4/stm32f4.dtsi:85 */
			compatible = "fixed-clock";   /* in zephyr/dts/arm/st/f4/stm32f4.dtsi:86 */
			clock-frequency = < 0x7d00 >; /* in zephyr/dts/arm/st/f4/stm32f4.dtsi:87 */
			status = "okay";              /* in zephyr/boards/st/stm32f469i_disco/stm32f469i_disco.dts:84 */
		};

		/* node '/clocks/pll' defined in zephyr/dts/arm/st/f4/stm32f4.dtsi:91 */
		pll: pll {
			#clock-cells = < 0x0 >;              /* in zephyr/dts/arm/st/f4/stm32f4.dtsi:92 */
			compatible = "st,stm32f4-pll-clock"; /* in zephyr/dts/arm/st/f4/stm32f4.dtsi:93 */
			div-m = < 0x8 >;                     /* in zephyr/boards/st/stm32f469i_disco/stm32f469i_disco.dts:93 */
			mul-n = < 0x150 >;                   /* in zephyr/boards/st/stm32f469i_disco/stm32f469i_disco.dts:94 */
			div-p = < 0x2 >;                     /* in zephyr/boards/st/stm32f469i_disco/stm32f469i_disco.dts:95 */
			div-q = < 0x7 >;                     /* in zephyr/boards/st/stm32f469i_disco/stm32f469i_disco.dts:96 */
			div-r = < 0x6 >;                     /* in zephyr/boards/st/stm32f469i_disco/stm32f469i_disco.dts:97 */
			clocks = < &clk_hse >;               /* in zephyr/boards/st/stm32f469i_disco/stm32f469i_disco.dts:98 */
			status = "okay";                     /* in zephyr/boards/st/stm32f469i_disco/stm32f469i_disco.dts:99 */
			phandle = < 0x2 >;                   /* in zephyr/boards/st/stm32f469i_disco/stm32f469i_disco.dts:113 */
		};

		/* node '/clocks/plli2s' defined in zephyr/dts/arm/st/f4/stm32f401.dtsi:11 */
		plli2s: plli2s {
			#clock-cells = < 0x0 >;                 /* in zephyr/dts/arm/st/f4/stm32f401.dtsi:12 */
			compatible = "st,stm32f4-plli2s-clock"; /* in zephyr/dts/arm/st/f4/stm32f401.dtsi:13 */
			status = "disabled";                    /* in zephyr/dts/arm/st/f4/stm32f401.dtsi:14 */
		};

		/* node '/clocks/pllsai' defined in zephyr/dts/arm/st/f4/stm32f427.dtsi:14 */
		pllsai: pllsai {
			compatible = "st,stm32fx-pllsai-clock"; /* in zephyr/dts/arm/st/f4/stm32f427.dtsi:15 */
			#clock-cells = < 0x0 >;                 /* in zephyr/dts/arm/st/f4/stm32f427.dtsi:16 */
			div-m = < 0x8 >;                        /* in zephyr/boards/st/stm32f469i_disco/stm32f469i_disco.dts:103 */
			mul-n = < 0x10a >;                      /* in zephyr/boards/st/stm32f469i_disco/stm32f469i_disco.dts:104 */
			div-p = < 0x2 >;                        /* in zephyr/boards/st/stm32f469i_disco/stm32f469i_disco.dts:105 */
			div-r = < 0x5 >;                        /* in zephyr/boards/st/stm32f469i_disco/stm32f469i_disco.dts:106 */
			div-divr = < 0x2 >;                     /* in zephyr/boards/st/stm32f469i_disco/stm32f469i_disco.dts:107 */
			clocks = < &clk_hse >;                  /* in zephyr/boards/st/stm32f469i_disco/stm32f469i_disco.dts:108 */
			status = "okay";                        /* in zephyr/boards/st/stm32f469i_disco/stm32f469i_disco.dts:109 */
		};
	};

	/* node '/mcos' defined in zephyr/dts/arm/st/f4/stm32f4.dtsi:98 */
	mcos {

		/* node '/mcos/mco1' defined in zephyr/dts/arm/st/f4/stm32f4.dtsi:99 */
		mco1: mco1 {
			compatible = "st,stm32-clock-mco"; /* in zephyr/dts/arm/st/f4/stm32f4.dtsi:100 */
			status = "disabled";               /* in zephyr/dts/arm/st/f4/stm32f4.dtsi:101 */
		};

		/* node '/mcos/mco2' defined in zephyr/dts/arm/st/f4/stm32f4.dtsi:104 */
		mco2: mco2 {
			compatible = "st,stm32-clock-mco"; /* in zephyr/dts/arm/st/f4/stm32f4.dtsi:105 */
			status = "disabled";               /* in zephyr/dts/arm/st/f4/stm32f4.dtsi:106 */
		};
	};

	/* node '/power@40007000' defined in zephyr/dts/arm/st/f4/stm32f4.dtsi:603 */
	pwr: power@40007000 {
		compatible = "st,stm32-pwr"; /* in zephyr/dts/arm/st/f4/stm32f4.dtsi:604 */
		reg = < 0x40007000 0x400 >;  /* in zephyr/dts/arm/st/f4/stm32f4.dtsi:605 */
		status = "disabled";         /* in zephyr/dts/arm/st/f4/stm32f4.dtsi:606 */
		wkup-pins-nb = < 0x1 >;      /* in zephyr/dts/arm/st/f4/stm32f4.dtsi:608 */
		#address-cells = < 0x1 >;    /* in zephyr/dts/arm/st/f4/stm32f4.dtsi:610 */
		#size-cells = < 0x0 >;       /* in zephyr/dts/arm/st/f4/stm32f4.dtsi:611 */

		/* node '/power@40007000/wkup-pin@1' defined in zephyr/dts/arm/st/f4/stm32f4.dtsi:613 */
		wkup-pin@1 {
			reg = < 0x1 >;                   /* in zephyr/dts/arm/st/f4/stm32f4.dtsi:614 */
			wkup-gpios = < &gpioa 0x0 0x1 >; /* in zephyr/dts/arm/st/f4/stm32f4.dtsi:615 */
		};
	};

	/* node '/dietemp' defined in zephyr/dts/arm/st/f4/stm32f4.dtsi:619 */
	die_temp: dietemp {
		compatible = "st,stm32-temp-cal"; /* in zephyr/dts/arm/st/f4/stm32f4.dtsi:620 */
		ts-cal1-addr = < 0x1fff7a2c >;    /* in zephyr/dts/arm/st/f4/stm32f4.dtsi:621 */
		ts-cal2-addr = < 0x1fff7a2e >;    /* in zephyr/dts/arm/st/f4/stm32f4.dtsi:622 */
		ts-cal1-temp = < 0x1e >;          /* in zephyr/dts/arm/st/f4/stm32f4.dtsi:623 */
		ts-cal2-temp = < 0x6e >;          /* in zephyr/dts/arm/st/f4/stm32f4.dtsi:624 */
		ts-cal-vrefanalog = < 0xce4 >;    /* in zephyr/dts/arm/st/f4/stm32f4.dtsi:625 */
		status = "disabled";              /* in zephyr/dts/arm/st/f4/stm32f4.dtsi:627 */
		io-channels = < &adc1 0x12 >;     /* in zephyr/dts/arm/st/f4/stm32f427.dtsi:140 */
	};

	/* node '/vref' defined in zephyr/dts/arm/st/f4/stm32f4.dtsi:630 */
	vref: vref {
		compatible = "st,stm32-vref";      /* in zephyr/dts/arm/st/f4/stm32f4.dtsi:631 */
		vrefint-cal-addr = < 0x1fff7a2a >; /* in zephyr/dts/arm/st/f4/stm32f4.dtsi:632 */
		vrefint-cal-mv = < 0xce4 >;        /* in zephyr/dts/arm/st/f4/stm32f4.dtsi:633 */
		io-channels = < &adc1 0x11 >;      /* in zephyr/dts/arm/st/f4/stm32f4.dtsi:634 */
		status = "disabled";               /* in zephyr/dts/arm/st/f4/stm32f4.dtsi:635 */
	};

	/* node '/vbat' defined in zephyr/dts/arm/st/f4/stm32f4.dtsi:638 */
	vbat: vbat {
		compatible = "st,stm32-vbat"; /* in zephyr/dts/arm/st/f4/stm32f4.dtsi:639 */
		ratio = < 0x4 >;              /* in zephyr/dts/arm/st/f4/stm32f4.dtsi:640 */
		io-channels = < &adc1 0x12 >; /* in zephyr/dts/arm/st/f4/stm32f4.dtsi:641 */
		status = "disabled";          /* in zephyr/dts/arm/st/f4/stm32f4.dtsi:642 */
	};

	/* node '/otgfs_phy' defined in zephyr/dts/arm/st/f4/stm32f4.dtsi:645 */
	otgfs_phy: otgfs_phy {
		compatible = "usb-nop-xceiv"; /* in zephyr/dts/arm/st/f4/stm32f4.dtsi:646 */
		#phy-cells = < 0x0 >;         /* in zephyr/dts/arm/st/f4/stm32f4.dtsi:647 */
		phandle = < 0xa >;            /* in zephyr/dts/arm/st/f4/stm32f4.dtsi:322 */
	};

	/* node '/smbus1' defined in zephyr/dts/arm/st/f4/stm32f4.dtsi:650 */
	smbus1: smbus1 {
		compatible = "st,stm32-smbus"; /* in zephyr/dts/arm/st/f4/stm32f4.dtsi:651 */
		#address-cells = < 0x1 >;      /* in zephyr/dts/arm/st/f4/stm32f4.dtsi:652 */
		#size-cells = < 0x0 >;         /* in zephyr/dts/arm/st/f4/stm32f4.dtsi:653 */
		i2c = < &i2c1 >;               /* in zephyr/dts/arm/st/f4/stm32f4.dtsi:654 */
		status = "disabled";           /* in zephyr/dts/arm/st/f4/stm32f4.dtsi:655 */
	};

	/* node '/smbus2' defined in zephyr/dts/arm/st/f4/stm32f4.dtsi:658 */
	smbus2: smbus2 {
		compatible = "st,stm32-smbus"; /* in zephyr/dts/arm/st/f4/stm32f4.dtsi:659 */
		#address-cells = < 0x1 >;      /* in zephyr/dts/arm/st/f4/stm32f4.dtsi:660 */
		#size-cells = < 0x0 >;         /* in zephyr/dts/arm/st/f4/stm32f4.dtsi:661 */
		i2c = < &i2c2 >;               /* in zephyr/dts/arm/st/f4/stm32f4.dtsi:662 */
		status = "disabled";           /* in zephyr/dts/arm/st/f4/stm32f4.dtsi:663 */
	};

	/* node '/smbus3' defined in zephyr/dts/arm/st/f4/stm32f4.dtsi:666 */
	smbus3: smbus3 {
		compatible = "st,stm32-smbus"; /* in zephyr/dts/arm/st/f4/stm32f4.dtsi:667 */
		#address-cells = < 0x1 >;      /* in zephyr/dts/arm/st/f4/stm32f4.dtsi:668 */
		#size-cells = < 0x0 >;         /* in zephyr/dts/arm/st/f4/stm32f4.dtsi:669 */
		i2c = < &i2c3 >;               /* in zephyr/dts/arm/st/f4/stm32f4.dtsi:670 */
		status = "disabled";           /* in zephyr/dts/arm/st/f4/stm32f4.dtsi:671 */
	};

	/* node '/otghs_fs_phy' defined in zephyr/dts/arm/st/f4/stm32f405.dtsi:302 */
	otghs_fs_phy: otghs_fs_phy {
		compatible = "usb-nop-xceiv"; /* in zephyr/dts/arm/st/f4/stm32f405.dtsi:303 */
		#phy-cells = < 0x0 >;         /* in zephyr/dts/arm/st/f4/stm32f405.dtsi:304 */
		phandle = < 0x1b >;           /* in zephyr/dts/arm/st/f4/stm32f405.dtsi:213 */
	};

	/* node '/memory@10000000' defined in zephyr/dts/arm/st/f4/stm32f469Xi.dtsi:10 */
	ccm0: memory@10000000 {
		compatible = "zephyr,memory-region",
		             "st,stm32-ccm";         /* in zephyr/dts/arm/st/f4/stm32f469Xi.dtsi:11 */
		reg = < 0x10000000 0x10000 >;        /* in zephyr/dts/arm/st/f4/stm32f469Xi.dtsi:12 */
		zephyr,memory-region = "CCM";        /* in zephyr/dts/arm/st/f4/stm32f469Xi.dtsi:13 */
	};

	/* node '/connector' defined in zephyr/boards/st/stm32f469i_disco/arduino_r3_connector.dtsi:10 */
	arduino_header: connector {
		compatible = "arduino-header-r3";          /* in zephyr/boards/st/stm32f469i_disco/arduino_r3_connector.dtsi:11 */
		#gpio-cells = < 0x2 >;                     /* in zephyr/boards/st/stm32f469i_disco/arduino_r3_connector.dtsi:12 */
		gpio-map-mask = < 0xffffffff 0xffffffc0 >; /* in zephyr/boards/st/stm32f469i_disco/arduino_r3_connector.dtsi:13 */
		gpio-map-pass-thru = < 0x0 0x3f >;         /* in zephyr/boards/st/stm32f469i_disco/arduino_r3_connector.dtsi:14 */
		gpio-map = < 0x0 0x0 &gpiob 0x1 0x0 >,
		           < 0x1 0x0 &gpioc 0x2 0x0 >,
		           < 0x2 0x0 &gpioc 0x3 0x0 >,
		           < 0x3 0x0 &gpioc 0x4 0x0 >,
		           < 0x4 0x0 &gpioc 0x5 0x0 >,
		           < 0x5 0x0 &gpioa 0x4 0x0 >,
		           < 0x6 0x0 &gpiog 0x9 0x0 >,
		           < 0x7 0x0 &gpiog 0xe 0x0 >,
		           < 0x8 0x0 &gpiog 0xf 0x0 >,
		           < 0x9 0x0 &gpioa 0x1 0x0 >,
		           < 0xa 0x0 &gpiog 0xc 0x0 >,
		           < 0xb 0x0 &gpioa 0x2 0x0 >,
		           < 0xc 0x0 &gpioa 0x6 0x0 >,
		           < 0xd 0x0 &gpiog 0xb 0x0 >,
		           < 0xe 0x0 &gpiog 0xa 0x0 >,
		           < 0xf 0x0 &gpioa 0x7 0x0 >,
		           < 0x10 0x0 &gpioh 0x6 0x0 >,
		           < 0x11 0x0 &gpiob 0xf 0x0 >,
		           < 0x12 0x0 &gpiob 0xe 0x0 >,
		           < 0x13 0x0 &gpiod 0x3 0x0 >,
		           < 0x14 0x0 &gpiob 0x9 0x0 >,
		           < 0x15 0x0 &gpiob 0x8 0x0 >;    /* in zephyr/boards/st/stm32f469i_disco/arduino_r3_connector.dtsi:15 */
	};

	/* node '/sdram@c0000000' defined in zephyr/boards/st/stm32f469i_disco/stm32f469i_disco.dts:27 */
	sdram1: sdram@c0000000 {
		compatible = "zephyr,memory-region",
		             "mmio-sram";            /* in zephyr/boards/st/stm32f469i_disco/stm32f469i_disco.dts:28 */
		device_type = "memory";              /* in zephyr/boards/st/stm32f469i_disco/stm32f469i_disco.dts:29 */
		reg = < 0xc0000000 0x1000000 >;      /* in zephyr/boards/st/stm32f469i_disco/stm32f469i_disco.dts:30 */
		zephyr,memory-region = "SDRAM1";     /* in zephyr/boards/st/stm32f469i_disco/stm32f469i_disco.dts:31 */
		phandle = < 0x56 >;                  /* in zephyr/boards/st/stm32f469i_disco/stm32f469i_disco.dts:261 */
	};

	/* node '/leds' defined in zephyr/boards/st/stm32f469i_disco/stm32f469i_disco.dts:34 */
	leds {
		compatible = "gpio-leds"; /* in zephyr/boards/st/stm32f469i_disco/stm32f469i_disco.dts:35 */

		/* node '/leds/led_1' defined in zephyr/boards/st/stm32f469i_disco/stm32f469i_disco.dts:37 */
		green_led_1: led_1 {
			gpios = < &gpiog 0x6 0x0 >; /* in zephyr/boards/st/stm32f469i_disco/stm32f469i_disco.dts:38 */
			label = "User LD1";         /* in zephyr/boards/st/stm32f469i_disco/stm32f469i_disco.dts:39 */
		};

		/* node '/leds/led_2' defined in zephyr/boards/st/stm32f469i_disco/stm32f469i_disco.dts:42 */
		orange_led_2: led_2 {
			gpios = < &gpiod 0x4 0x0 >; /* in zephyr/boards/st/stm32f469i_disco/stm32f469i_disco.dts:43 */
			label = "User LD2";         /* in zephyr/boards/st/stm32f469i_disco/stm32f469i_disco.dts:44 */
		};

		/* node '/leds/led_3' defined in zephyr/boards/st/stm32f469i_disco/stm32f469i_disco.dts:47 */
		red_led_3: led_3 {
			gpios = < &gpiod 0x5 0x0 >; /* in zephyr/boards/st/stm32f469i_disco/stm32f469i_disco.dts:48 */
			label = "User LD3";         /* in zephyr/boards/st/stm32f469i_disco/stm32f469i_disco.dts:49 */
		};

		/* node '/leds/led_4' defined in zephyr/boards/st/stm32f469i_disco/stm32f469i_disco.dts:52 */
		blue_led_4: led_4 {
			gpios = < &gpiok 0x3 0x0 >; /* in zephyr/boards/st/stm32f469i_disco/stm32f469i_disco.dts:53 */
			label = "User LD4";         /* in zephyr/boards/st/stm32f469i_disco/stm32f469i_disco.dts:54 */
		};
	};

	/* node '/lvgl_pointer' defined in zephyr/boards/st/stm32f469i_disco/stm32f469i_disco.dts:58 */
	lvgl_pointer {
		compatible = "zephyr,lvgl-pointer-input"; /* in zephyr/boards/st/stm32f469i_disco/stm32f469i_disco.dts:59 */
		input = < &ft5336 >;                      /* in zephyr/boards/st/stm32f469i_disco/stm32f469i_disco.dts:60 */
		invert-y;                                 /* in zephyr/boards/st/stm32f469i_disco/stm32f469i_disco.dts:61 */
	};

	/* node '/gpio_keys' defined in zephyr/boards/st/stm32f469i_disco/stm32f469i_disco.dts:64 */
	gpio_keys {
		compatible = "gpio-keys"; /* in zephyr/boards/st/stm32f469i_disco/stm32f469i_disco.dts:65 */

		/* node '/gpio_keys/button' defined in zephyr/boards/st/stm32f469i_disco/stm32f469i_disco.dts:67 */
		user_button: button {
			label = "User";             /* in zephyr/boards/st/stm32f469i_disco/stm32f469i_disco.dts:68 */
			gpios = < &gpioa 0x0 0x1 >; /* in zephyr/boards/st/stm32f469i_disco/stm32f469i_disco.dts:69 */
			zephyr,code = < 0xb >;      /* in zephyr/boards/st/stm32f469i_disco/stm32f469i_disco.dts:70 */
		};
	};
};
